VERSION ""

NS_ :

BS_:

BU_: RF_CT3

BO_ 1 Pos1_SlipAngle_Signals: 8 Vector__XXX
 SG_ Pos1_SlipAngle_20Hz : 0|16@1- (0.0013733329264,0) [-45|44.9986] "Degrees" Vector__XXX

BO_ 2 Pos2_SlipAngle_Signals: 8 Vector__XXX
 SG_ Pos2_SlipAngle_20Hz : 0|16@1- (0.0013733329264,0) [-45|44.9986] "Degrees" Vector__XXX

BO_ 3 Pos3_SlipAngle_Signals: 8 Vector__XXX
 SG_ Pos3_SlipAngle_20Hz : 0|16@1- (0.0013733329264,0) [-45|44.9986] "Degrees" Vector__XXX

BO_ 4 Pos4_SlipAngle_Signals: 8 Vector__XXX
 SG_ Pos4_SlipAngle_20Hz : 0|16@1- (0.0013733329264,0) [-45|44.9986] "Degrees" Vector__XXX

BO_ 5 Pos5_SlipAngle_Signals: 8 Vector__XXX
 SG_ Pos5_SlipAngle_20Hz : 0|16@1- (0.0013733329264,0) [-45|44.9986] "Degrees" Vector__XXX

BO_ 6 Pos6_SlipAngle_Signals: 8 Vector__XXX
 SG_ Pos6_SlipAngle_20Hz : 0|16@1- (0.0013733329264,0) [-45|44.9986] "Degrees" Vector__XXX

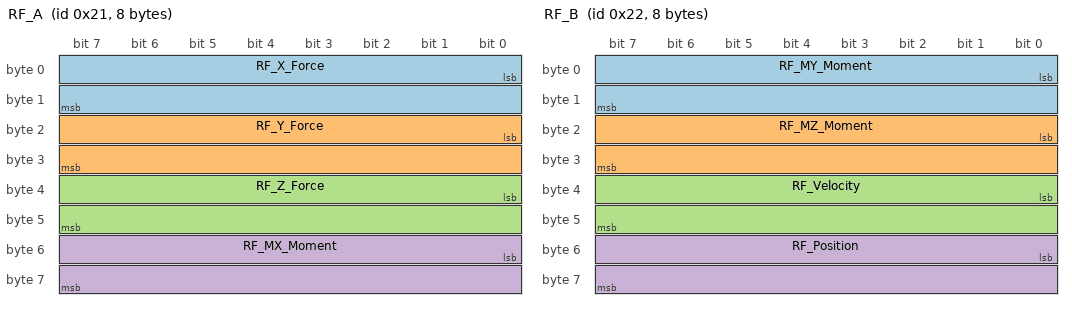
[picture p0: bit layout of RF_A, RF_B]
BO_ 33 RF_A: 8 RF_CT3
 SG_ RF_X_Force : 0|16@1- (1.220703125,0) [-40000|40000] "N" Vector__XXX
 SG_ RF_Y_Force : 16|16@1- (0.6103515625,0) [-20000|20000] "N" Vector__XXX
 SG_ RF_Z_Force : 32|16@1- (1.220703125,0) [-40000|40000] "N" Vector__XXX
 SG_ RF_MX_Moment : 48|16@1- (0.18310546875,0) [-6000|6000] "Nm" Vector__XXX

BO_ 34 RF_B: 8 RF_CT3
 SG_ RF_MY_Moment : 0|16@1- (0.18310546875,0) [-6000|6000] "Nm" Vector__XXX
 SG_ RF_MZ_Moment : 16|16@1- (0.18310546875,0) [-6000|6000] "Nm" Vector__XXX
 SG_ RF_Velocity : 32|16@1- (0.06103515625,0) [-2000|2000] "rpm" Vector__XXX
 SG_ RF_Position : 48|16@1- (0.010986328125,0) [0|360] "degrees" Vector__XXX

BO_ 35 RF_C: 8 RF_CT3
 SG_ RF_X_Acceleration : 0|16@1- (0.0030517578125,0) [-100|100] "g" Vector__XXX
 SG_ RF_Y_Acceleration : 16|16@1- (0.0030517578125,0) [-100|100] "g" Vector__XXX
 SG_ RF_Z_Acceleration : 32|16@1- (0.0030517578125,0) [-100|100] "g" Vector__XXX

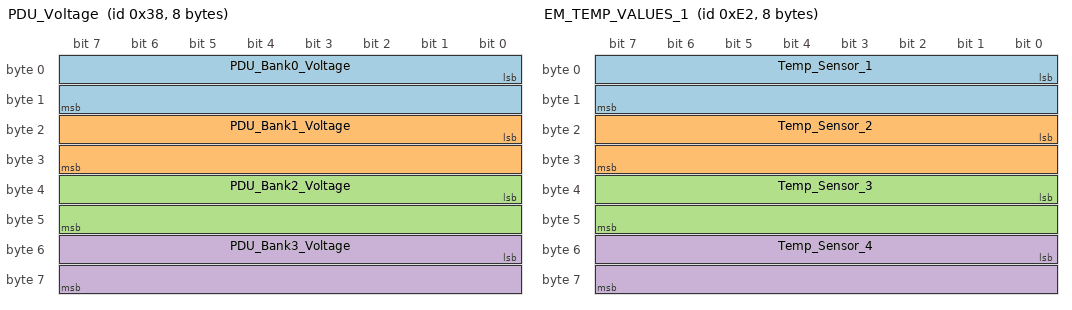
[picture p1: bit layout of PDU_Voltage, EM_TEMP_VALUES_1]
BO_ 56 PDU_Voltage: 8 PDU
 SG_ PDU_Bank0_Voltage : 0|16@1+ (0.001,0) [0|0] "V" Vector__XXX
 SG_ PDU_Bank1_Voltage : 16|16@1+ (0.001,0) [0|0] "V" Vector__XXX
 SG_ PDU_Bank2_Voltage : 32|16@1+ (0.001,0) [0|0] "V" Vector__XXX
 SG_ PDU_Bank3_Voltage : 48|16@1+ (0.001,0) [0|0] "V" Vector__XXX

BO_ 57 PDU_Currents: 8 PDU
 SG_ PDU_ChannelMux M : 0|4@1+ (1,0) [0|6] "" Vector__XXX
 SG_ PDU_Channel0 m0 : 4|12@1+ (0.0025,0) [0|0] "A" Vector__XXX
 SG_ PDU_Channel1 m0 : 16|12@1+ (0.0025,0) [0|0] "A" Vector__XXX
 SG_ PDU_Channel2 m0 : 28|12@1+ (0.0025,0) [0|0] "A" Vector__XXX
 SG_ PDU_Channel3 m0 : 40|12@1+ (0.0025,0) [0|0] "A" Vector__XXX
 SG_ PDU_Channel4 m0 : 52|12@1+ (0.0025,0) [0|0] "A" Vector__XXX
 SG_ PDU_Channel5 m1 : 4|12@1+ (0.0025,0) [0|0] "A" Vector__XXX
 SG_ PDU_Channel6 m1 : 16|12@1+ (0.0025,0) [0|0] "A" Vector__XXX
 SG_ PDU_Channel7 m1 : 28|12@1+ (0.0025,0) [0|0] "A" Vector__XXX
 SG_ PDU_Channel8 m1 : 40|12@1+ (0.0025,0) [0|0] "A" Vector__XXX
 SG_ PDU_Channel9 m1 : 52|12@1+ (0.0025,0) [0|0] "A" Vector__XXX
 SG_ PDU_Channel10 m2 : 4|12@1+ (0.0025,0) [0|0] "A" Vector__XXX
 SG_ PDU_Channel11 m2 : 16|12@1+ (0.0025,0) [0|0] "A" Vector__XXX
 SG_ PDU_Channel12 m2 : 28|12@1+ (0.0025,0) [0|0] "A" Vector__XXX
 SG_ PDU_Channel13 m2 : 40|12@1+ (0.0025,0) [0|0] "A" Vector__XXX
 SG_ PDU_Channel14 m2 : 52|12@1+ (0.0025,0) [0|0] "A" Vector__XXX
 SG_ PDU_Channel15 m3 : 4|12@1+ (0.0025,0) [0|0] "A" Vector__XXX
 SG_ PDU_Channel16 m3 : 16|12@1+ (0.0025,0) [0|0] "A" Vector__XXX
 SG_ PDU_Channel17 m3 : 28|12@1+ (0.0025,0) [0|0] "A" Vector__XXX
 SG_ PDU_Channel18 m3 : 40|12@1+ (0.0025,0) [0|0] "A" Vector__XXX
 SG_ PDU_Channel19 m3 : 52|12@1+ (0.0025,0) [0|0] "A" Vector__XXX
 SG_ PDU_Channel20 m4 : 4|12@1+ (0.0025,0) [0|0] "A" Vector__XXX
 SG_ PDU_Channel21 m4 : 16|12@1+ (0.0025,0) [0|0] "A" Vector__XXX
 SG_ PDU_Channel22 m4 : 28|12@1+ (0.0025,0) [0|0] "A" Vector__XXX
 SG_ PDU_Channel23 m4 : 40|12@1+ (0.0025,0) [0|0] "A" Vector__XXX
 SG_ PDU_Channel24 m4 : 52|12@1+ (0.0025,0) [0|0] "A" Vector__XXX
 SG_ PDU_Channel25 m5 : 4|12@1+ (0.0025,0) [0|0] "A" Vector__XXX
 SG_ PDU_Channel26 m5 : 16|12@1+ (0.0025,0) [0|0] "A" Vector__XXX
 SG_ PDU_Channel27 m5 : 28|12@1+ (0.0025,0) [0|0] "A" Vector__XXX
 SG_ PDU_Channel28 m5 : 40|12@1+ (0.0025,0) [0|0] "A" Vector__XXX
 SG_ PDU_Channel29 m5 : 52|12@1+ (0.0025,0) [0|0] "A" Vector__XXX
 SG_ PDU_Channel30 m6 : 4|12@1+ (0.0025,0) [0|0] "A" Vector__XXX
 SG_ PDU_Channel31 m6 : 16|12@1+ (0.0025,0) [0|0] "A" Vector__XXX

BO_ 226 EM_TEMP_VALUES_1: 8 Vector__XXX
 SG_ Temp_Sensor_1 : 0|16@1- (0.0625,0) [0|255] "C" Vector__XXX
 SG_ Temp_Sensor_2 : 16|16@1- (0.0625,0) [0|255] "C" Vector__XXX
 SG_ Temp_Sensor_3 : 32|16@1- (0.0625,0) [0|255] "C" Vector__XXX
 SG_ Temp_Sensor_4 : 48|16@1- (0.0625,0) [0|255] "C" Vector__XXX

BO_ 225 EM_TEMP_VALUES_2: 2 Vector_XXX
 SG_ Temp_Sensor_5 : 0|16@1- (0.0625,0) [0|255] "C" Vector__XXX

BO_ 224 EM_OUTPUT_VALUES: 8 EM
 SG_ CURRENT: 0|16@1- (0.1,0) [0|0] "A" Vector__XXX
 SG_ VOLTAGE: 16|16@1+ (0.01,0) [0|0] "V" Vector__XXX
 SG_ POWER: 32|18@1+ (1,0) [0|0] "W" Vector__XXX

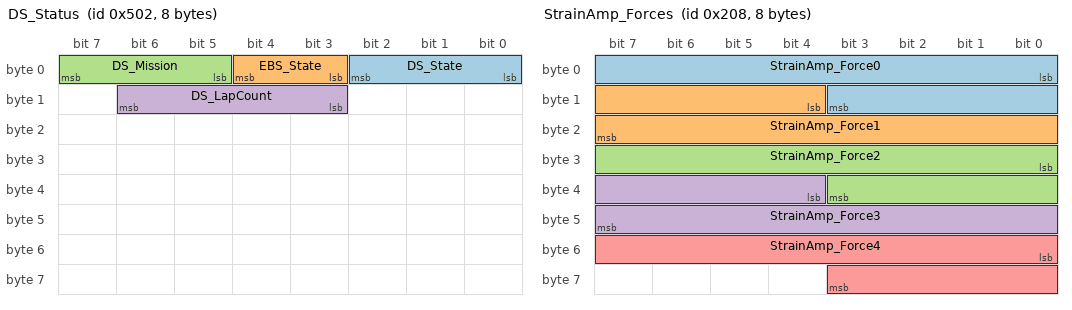
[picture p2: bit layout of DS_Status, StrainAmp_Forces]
BO_ 1282 DS_Status: 8 DS
 SG_ DS_State : 0|3@1+ (1,0) [0|0] "" Vector__XXX
 SG_ EBS_State : 3|2@1+ (1,0) [0|0] "" Vector__XXX
 SG_ DS_Mission : 5|3@1+ (1,0) [0|0] "" Vector__XXX
 SG_ DS_LapCount : 11|4@1+ (1,0) [0|0] "" Vector__XXX

BO_ 384 PIT_Pressures: 8 PIT
 SG_ PIT_PressureMux M : 0|8@1+ (1,0) [0|255] "" Vector__XXX
 SG_ PIT_Pressure1 m0 : 15|16@0+ (0.01,600) [600|1200] "mbar" Vector__XXX
 SG_ PIT_Pressure2 m0 : 31|16@0+ (0.01,600) [600|1200] "mbar" Vector__XXX
 SG_ PIT_Pressure3 m0 : 47|16@0+ (0.01,600) [600|1200] "mbar" Vector__XXX
 SG_ PIT_PressureRange m0 : 56|8@1+ (1,0) [0|3] "" Vector__XXX
 SG_ PIT_Pressure4 m1 : 15|16@0+ (0.01,600) [600|1200] "mbar" Vector__XXX
 SG_ PIT_Pressure5 m1 : 31|16@0+ (0.01,600) [600|1200] "mbar" Vector__XXX
 SG_ PIT_Pressure6 m1 : 47|16@0+ (0.01,600) [600|1200] "mbar" Vector__XXX
 SG_ PIT_Temperature m1 : 56|8@1- (1,0) [0|0] "degC" Vector__XXX
 SG_ PIT_Pressure7 m2 : 15|16@0+ (0.01,600) [600|1200] "mbar" Vector__XXX
 SG_ PIT_Pressure8 m2 : 31|16@0+ (0.01,600) [600|1200] "mbar" Vector__XXX
 SG_ PIT_SensorNum m2 : 47|16@0+ (1,0) [0|0] "" Vector__XXX

BO_ 506 OutboardAccelAvg: 6 OA
 SG_ OAAvg_AccelX : 0|16@1- (0.001,0) [-32.768|32.767] "g" Vector_XXX
 SG_ OAAvg_AccelY : 16|16@1- (0.001,0) [-32.768|32.767] "g" Vector_XXX
 SG_ OAAvg_AccelZ : 32|16@1- (0.001,0) [-32.768|32.767] "g" Vector_XXX

BO_ 507 OutboardAccelMin: 6 OA
 SG_ OAMin_AccelX : 0|16@1- (0.001,0) [-32.768|32.767] "g" Vector_XXX
 SG_ OAMin_AccelY : 16|16@1- (0.001,0) [-32.768|32.767] "g" Vector_XXX
 SG_ OAMin_AccelZ : 32|16@1- (0.001,0) [-32.768|32.767] "g" Vector_XXX

BO_ 508 OutboardAccelMax: 6 OA
 SG_ OAMax_AccelX : 0|16@1- (0.001,0) [-32.768|32.767] "g" Vector_XXX
 SG_ OAMax_AccelY : 16|16@1- (0.001,0) [-32.768|32.767] "g" Vector_XXX
 SG_ OAMax_AccelZ : 32|16@1- (0.001,0) [-32.768|32.767] "g" Vector_XXX

BO_ 520 StrainAmp_Forces: 8 SA
 SG_ StrainAmp_Force0 : 0|12@1- (2,0) [0|0] "lbf" Vector__XXX
 SG_ StrainAmp_Force1 : 12|12@1- (2,0) [0|0] "lbf" Vector__XXX
 SG_ StrainAmp_Force2 : 24|12@1- (2,0) [0|0] "lbf" Vector__XXX
 SG_ StrainAmp_Force3 : 36|12@1- (2,0) [0|0] "lbf" Vector__XXX
 SG_ StrainAmp_Force4 : 48|12@1- (2,0) [0|0] "lbf" Vector__XXX

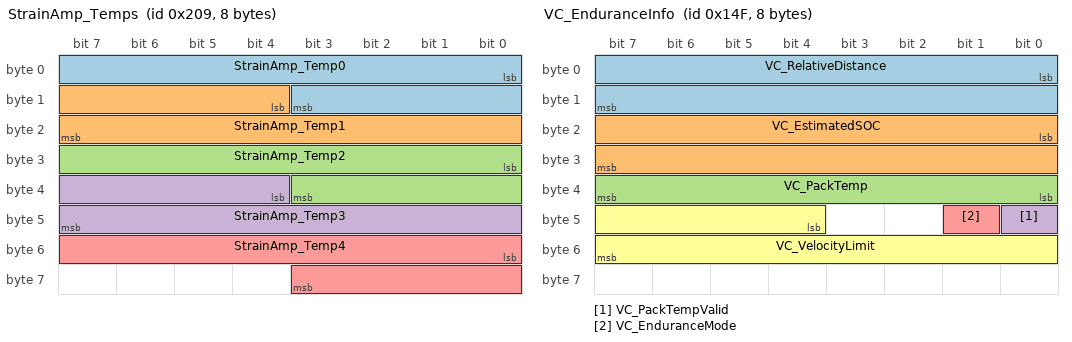
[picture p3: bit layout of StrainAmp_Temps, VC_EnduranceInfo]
BO_ 521 StrainAmp_Temps: 8 SA
 SG_ StrainAmp_Temp0 : 0|12@1- (0.05,0) [0|0] "degC" Vector__XXX
 SG_ StrainAmp_Temp1 : 12|12@1- (0.05,0) [0|0] "degC" Vector__XXX
 SG_ StrainAmp_Temp2 : 24|12@1- (0.05,0) [0|0] "degC" Vector__XXX
 SG_ StrainAmp_Temp3 : 36|12@1- (0.05,0) [0|0] "degC" Vector__XXX
 SG_ StrainAmp_Temp4 : 48|12@1- (0.05,0) [0|0] "degC" Vector__XXX

BO_ 300 VC_PDU_Control: 2 VC
 SG_ VC_Inverter_PWM : 0|5@1+ (1,0) [0|25] "" Vector__XXX
 SG_ VC_Motor_PWM : 5|5@1+ (1,0) [0|25] "" Vector__XXX

BO_ 335 VC_EnduranceInfo: 8 VC
 SG_ VC_RelativeDistance : 0|16@1+ (0.0000152587890625,0) [0|0] "" Vector__XXX
 SG_ VC_EstimatedSOC : 16|16@1+ (0.0000152587890625,0) [0|0] "" Vector__XXX
 SG_ VC_PackTemp : 32|8@1+ (0.00390625,0) [0|0] "" Vector__XXX
 SG_ VC_PackTempValid : 40|1@1+ (1,0) [0|0] "" Vector__XXX
 SG_ VC_EnduranceMode : 41|1@1+ (1,0) [0|0] "" Vector__XXX
 SG_ VC_VelocityLimit : 44|12@1+ (0.01,0) [0|0] "m/s" Vector__XXX

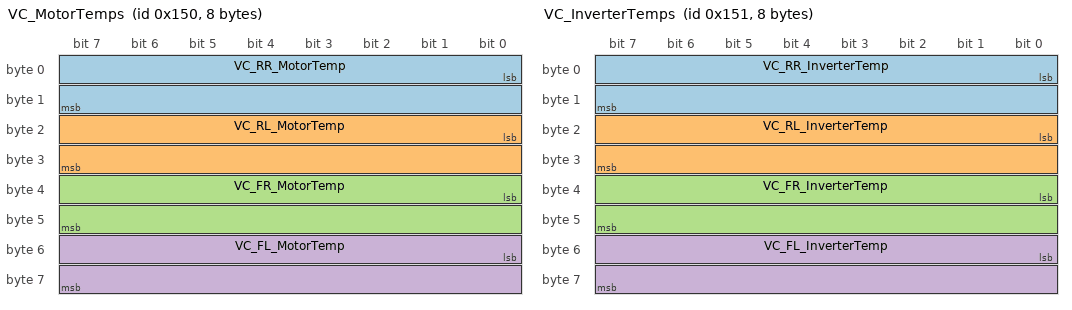
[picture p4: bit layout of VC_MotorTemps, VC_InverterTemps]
BO_ 336 VC_MotorTemps : 8 VC
 SG_ VC_RR_MotorTemp : 0|16@1- (0.1,0) [0|0] "degC" Vector__XXX
 SG_ VC_RL_MotorTemp : 16|16@1- (0.1,0) [0|0] "degC" Vector__XXX
 SG_ VC_FR_MotorTemp : 32|16@1- (0.1,0) [0|0] "degC" Vector__XXX
 SG_ VC_FL_MotorTemp : 48|16@1- (0.1,0) [0|0] "degC" Vector__XXX

BO_ 337 VC_InverterTemps : 8 VC
 SG_ VC_RR_InverterTemp : 0|16@1- (0.1,0) [0|0] "degC" Vector__XXX
 SG_ VC_RL_InverterTemp : 16|16@1- (0.1,0) [0|0] "degC" Vector__XXX
 SG_ VC_FR_InverterTemp : 32|16@1- (0.1,0) [0|0] "degC" Vector__XXX
 SG_ VC_FL_InverterTemp : 48|16@1- (0.1,0) [0|0] "degC" Vector__XXX

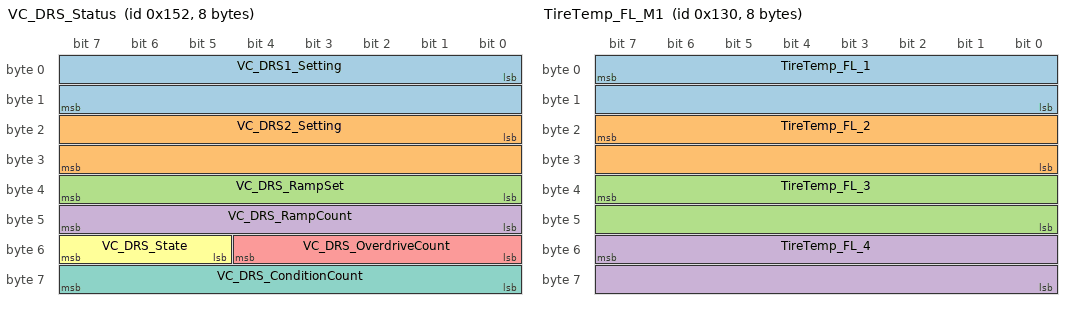
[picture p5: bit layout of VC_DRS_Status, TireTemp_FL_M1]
BO_ 338 VC_DRS_Status : 8 VC
 SG_ VC_DRS1_Setting : 0|16@1+ (1,0) [0|0] "" Vector__XXX
 SG_ VC_DRS2_Setting : 16|16@1+ (1,0) [0|0] "" Vector__XXX
 SG_ VC_DRS_RampSet : 32|8@1+ (1,0) [0|0] "" Vector__XXX
 SG_ VC_DRS_RampCount : 40|8@1+ (1,0) [0|0] "" Vector__XXX
 SG_ VC_DRS_OverdriveCount : 48|5@1+ (1,0) [0|0] "" Vector__XXX
 SG_ VC_DRS_State : 53|3@1+ (1,0) [0|0] "" Vector__XXX
 SG_ VC_DRS_ConditionCount : 56|8@1+ (1,0) [0|0] "" Vector__XXX

BO_ 304 TireTemp_FL_M1: 8 IRTEMP
 SG_ TireTemp_FL_1 : 7|16@0+ (0.1,-100) [-20|950] "degC" Vector__XXX
 SG_ TireTemp_FL_2 : 23|16@0+ (0.1,-100) [-20|950] "degC" Vector__XXX
 SG_ TireTemp_FL_3 : 39|16@0+ (0.1,-100) [-20|950] "degC" Vector__XXX
 SG_ TireTemp_FL_4 : 55|16@0+ (0.1,-100) [-20|950] "degC" Vector__XXX

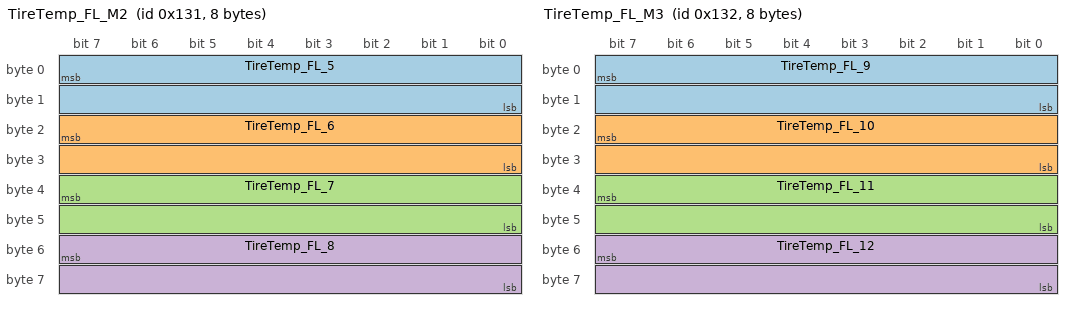
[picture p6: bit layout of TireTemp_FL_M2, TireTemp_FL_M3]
BO_ 305 TireTemp_FL_M2: 8 IRTEMP
 SG_ TireTemp_FL_5 : 7|16@0+ (0.1,-100) [-20|950] "degC" Vector__XXX
 SG_ TireTemp_FL_6 : 23|16@0+ (0.1,-100) [-20|950] "degC" Vector__XXX
 SG_ TireTemp_FL_7 : 39|16@0+ (0.1,-100) [-20|950] "degC" Vector__XXX
 SG_ TireTemp_FL_8 : 55|16@0+ (0.1,-100) [-20|950] "degC" Vector__XXX

BO_ 306 TireTemp_FL_M3: 8 IRTEMP
 SG_ TireTemp_FL_9 : 7|16@0+ (0.1,-100) [-20|950] "degC" Vector__XXX
 SG_ TireTemp_FL_10 : 23|16@0+ (0.1,-100) [-20|950] "degC" Vector__XXX
 SG_ TireTemp_FL_11 : 39|16@0+ (0.1,-100) [-20|950] "degC" Vector__XXX
 SG_ TireTemp_FL_12 : 55|16@0+ (0.1,-100) [-20|950] "degC" Vector__XXX

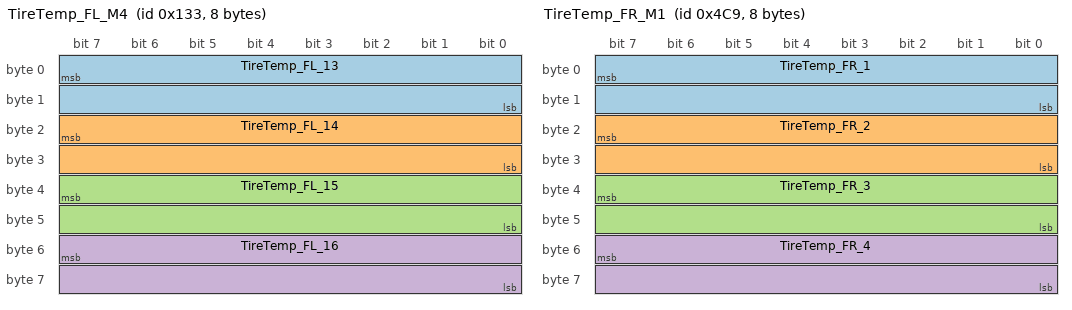
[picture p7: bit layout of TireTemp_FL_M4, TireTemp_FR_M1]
BO_ 307 TireTemp_FL_M4: 8 IRTEMP
 SG_ TireTemp_FL_13 : 7|16@0+ (0.1,-100) [-20|950] "degC" Vector__XXX
 SG_ TireTemp_FL_14 : 23|16@0+ (0.1,-100) [-20|950] "degC" Vector__XXX
 SG_ TireTemp_FL_15 : 39|16@0+ (0.1,-100) [-20|950] "degC" Vector__XXX
 SG_ TireTemp_FL_16 : 55|16@0+ (0.1,-100) [-20|950] "degC" Vector__XXX

BO_ 308 TireTemp_FL_M5: 8 IRTEMP
 SG_ TireTemp_FL_Sensor : 7|16@0+ (0.1,-100) [-20|85] "degC" Vector__XXX

BO_ 1225 TireTemp_FR_M1: 8 IRTEMP
 SG_ TireTemp_FR_1 : 7|16@0+ (0.1,-100) [-20|950] "degC" Vector__XXX
 SG_ TireTemp_FR_2 : 23|16@0+ (0.1,-100) [-20|950] "degC" Vector__XXX
 SG_ TireTemp_FR_3 : 39|16@0+ (0.1,-100) [-20|950] "degC" Vector__XXX
 SG_ TireTemp_FR_4 : 55|16@0+ (0.1,-100) [-20|950] "degC" Vector__XXX

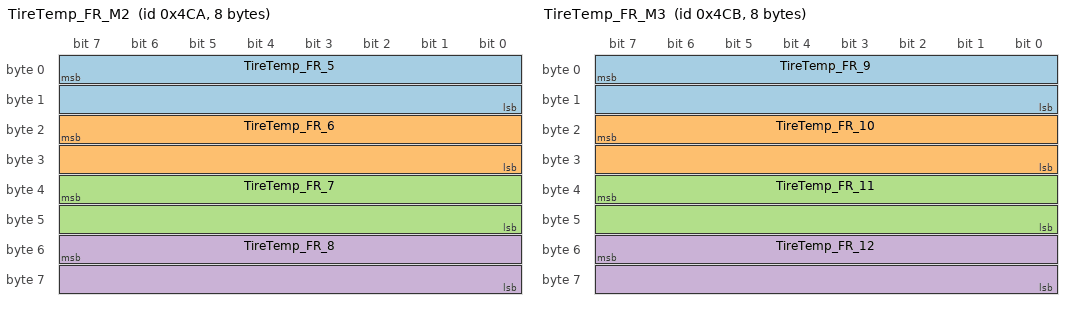
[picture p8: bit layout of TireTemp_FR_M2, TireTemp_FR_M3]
BO_ 1226 TireTemp_FR_M2: 8 IRTEMP
 SG_ TireTemp_FR_5 : 7|16@0+ (0.1,-100) [-20|950] "degC" Vector__XXX
 SG_ TireTemp_FR_6 : 23|16@0+ (0.1,-100) [-20|950] "degC" Vector__XXX
 SG_ TireTemp_FR_7 : 39|16@0+ (0.1,-100) [-20|950] "degC" Vector__XXX
 SG_ TireTemp_FR_8 : 55|16@0+ (0.1,-100) [-20|950] "degC" Vector__XXX

BO_ 1227 TireTemp_FR_M3: 8 IRTEMP
 SG_ TireTemp_FR_9 : 7|16@0+ (0.1,-100) [-20|950] "degC" Vector__XXX
 SG_ TireTemp_FR_10 : 23|16@0+ (0.1,-100) [-20|950] "degC" Vector__XXX
 SG_ TireTemp_FR_11 : 39|16@0+ (0.1,-100) [-20|950] "degC" Vector__XXX
 SG_ TireTemp_FR_12 : 55|16@0+ (0.1,-100) [-20|950] "degC" Vector__XXX

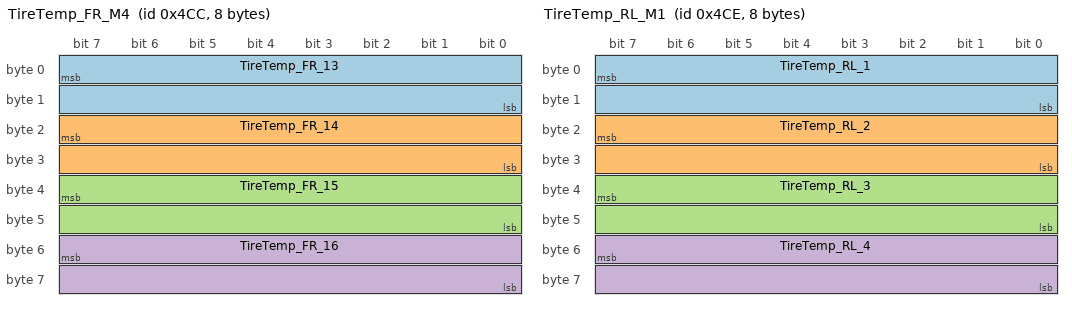
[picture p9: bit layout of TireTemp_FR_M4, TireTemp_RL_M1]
BO_ 1228 TireTemp_FR_M4: 8 IRTEMP
 SG_ TireTemp_FR_13 : 7|16@0+ (0.1,-100) [-20|950] "degC" Vector__XXX
 SG_ TireTemp_FR_14 : 23|16@0+ (0.1,-100) [-20|950] "degC" Vector__XXX
 SG_ TireTemp_FR_15 : 39|16@0+ (0.1,-100) [-20|950] "degC" Vector__XXX
 SG_ TireTemp_FR_16 : 55|16@0+ (0.1,-100) [-20|950] "degC" Vector__XXX

BO_ 1229 TireTemp_FR_M5: 8 IRTEMP
 SG_ TireTemp_FR_Sensor : 7|16@0+ (0.1,-100) [-20|85] "degC" Vector__XXX

BO_ 1230 TireTemp_RL_M1: 8 IRTEMP
 SG_ TireTemp_RL_1 : 7|16@0+ (0.1,-100) [-20|950] "degC" Vector__XXX
 SG_ TireTemp_RL_2 : 23|16@0+ (0.1,-100) [-20|950] "degC" Vector__XXX
 SG_ TireTemp_RL_3 : 39|16@0+ (0.1,-100) [-20|950] "degC" Vector__XXX
 SG_ TireTemp_RL_4 : 55|16@0+ (0.1,-100) [-20|950] "degC" Vector__XXX

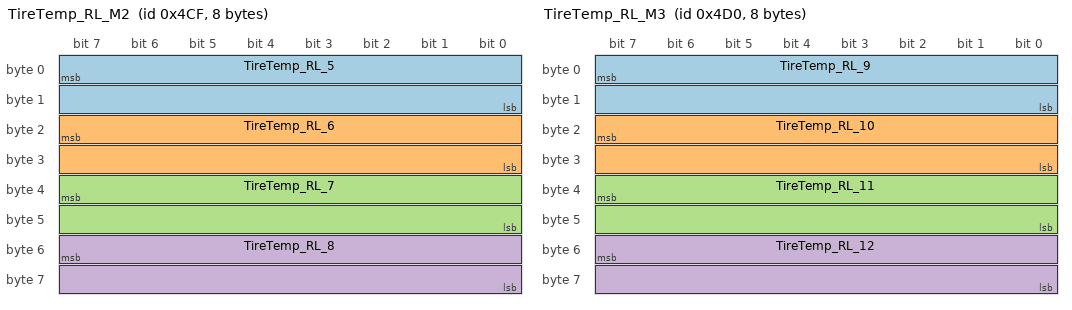
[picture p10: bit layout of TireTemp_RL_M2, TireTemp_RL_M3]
BO_ 1231 TireTemp_RL_M2: 8 IRTEMP
 SG_ TireTemp_RL_5 : 7|16@0+ (0.1,-100) [-20|950] "degC" Vector__XXX
 SG_ TireTemp_RL_6 : 23|16@0+ (0.1,-100) [-20|950] "degC" Vector__XXX
 SG_ TireTemp_RL_7 : 39|16@0+ (0.1,-100) [-20|950] "degC" Vector__XXX
 SG_ TireTemp_RL_8 : 55|16@0+ (0.1,-100) [-20|950] "degC" Vector__XXX

BO_ 1232 TireTemp_RL_M3: 8 IRTEMP
 SG_ TireTemp_RL_9 : 7|16@0+ (0.1,-100) [-20|950] "degC" Vector__XXX
 SG_ TireTemp_RL_10 : 23|16@0+ (0.1,-100) [-20|950] "degC" Vector__XXX
 SG_ TireTemp_RL_11 : 39|16@0+ (0.1,-100) [-20|950] "degC" Vector__XXX
 SG_ TireTemp_RL_12 : 55|16@0+ (0.1,-100) [-20|950] "degC" Vector__XXX

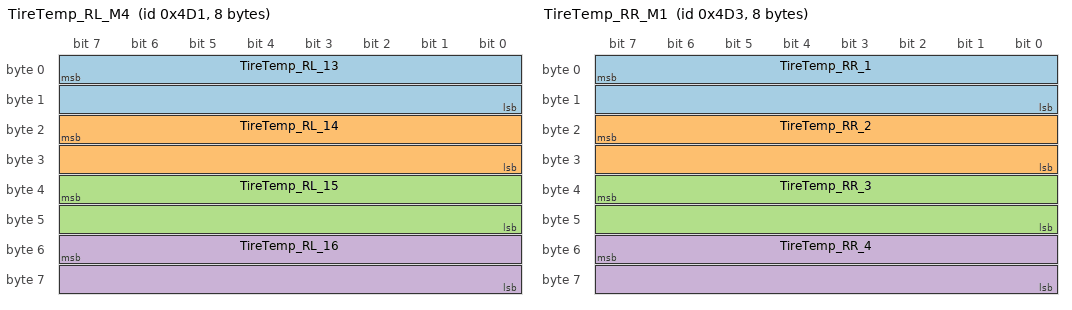
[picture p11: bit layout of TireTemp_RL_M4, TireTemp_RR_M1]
BO_ 1233 TireTemp_RL_M4: 8 IRTEMP
 SG_ TireTemp_RL_13 : 7|16@0+ (0.1,-100) [-20|950] "degC" Vector__XXX
 SG_ TireTemp_RL_14 : 23|16@0+ (0.1,-100) [-20|950] "degC" Vector__XXX
 SG_ TireTemp_RL_15 : 39|16@0+ (0.1,-100) [-20|950] "degC" Vector__XXX
 SG_ TireTemp_RL_16 : 55|16@0+ (0.1,-100) [-20|950] "degC" Vector__XXX

BO_ 1234 TireTemp_RL_M5: 8 IRTEMP
 SG_ TireTemp_RL_Sensor : 7|16@0+ (0.1,-100) [-20|85] "degC" Vector__XXX

BO_ 1235 TireTemp_RR_M1: 8 IRTEMP
 SG_ TireTemp_RR_1 : 7|16@0+ (0.1,-100) [-20|950] "degC" Vector__XXX
 SG_ TireTemp_RR_2 : 23|16@0+ (0.1,-100) [-20|950] "degC" Vector__XXX
 SG_ TireTemp_RR_3 : 39|16@0+ (0.1,-100) [-20|950] "degC" Vector__XXX
 SG_ TireTemp_RR_4 : 55|16@0+ (0.1,-100) [-20|950] "degC" Vector__XXX

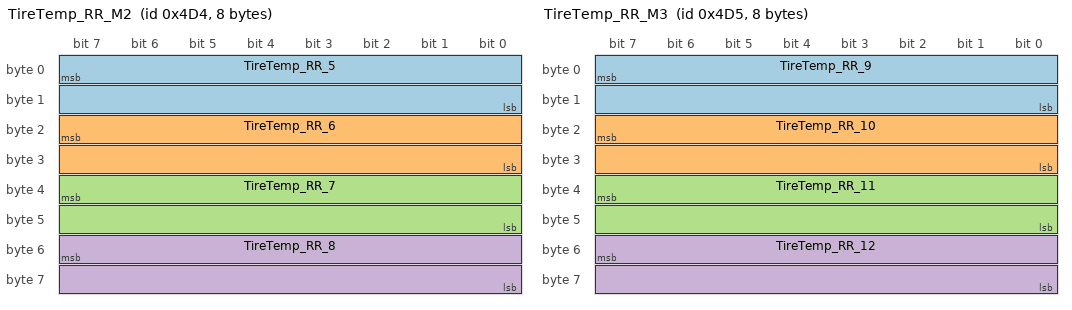
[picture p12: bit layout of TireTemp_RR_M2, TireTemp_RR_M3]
BO_ 1236 TireTemp_RR_M2: 8 IRTEMP
 SG_ TireTemp_RR_5 : 7|16@0+ (0.1,-100) [-20|950] "degC" Vector__XXX
 SG_ TireTemp_RR_6 : 23|16@0+ (0.1,-100) [-20|950] "degC" Vector__XXX
 SG_ TireTemp_RR_7 : 39|16@0+ (0.1,-100) [-20|950] "degC" Vector__XXX
 SG_ TireTemp_RR_8 : 55|16@0+ (0.1,-100) [-20|950] "degC" Vector__XXX

BO_ 1237 TireTemp_RR_M3: 8 IRTEMP
 SG_ TireTemp_RR_9 : 7|16@0+ (0.1,-100) [-20|950] "degC" Vector__XXX
 SG_ TireTemp_RR_10 : 23|16@0+ (0.1,-100) [-20|950] "degC" Vector__XXX
 SG_ TireTemp_RR_11 : 39|16@0+ (0.1,-100) [-20|950] "degC" Vector__XXX
 SG_ TireTemp_RR_12 : 55|16@0+ (0.1,-100) [-20|950] "degC" Vector__XXX

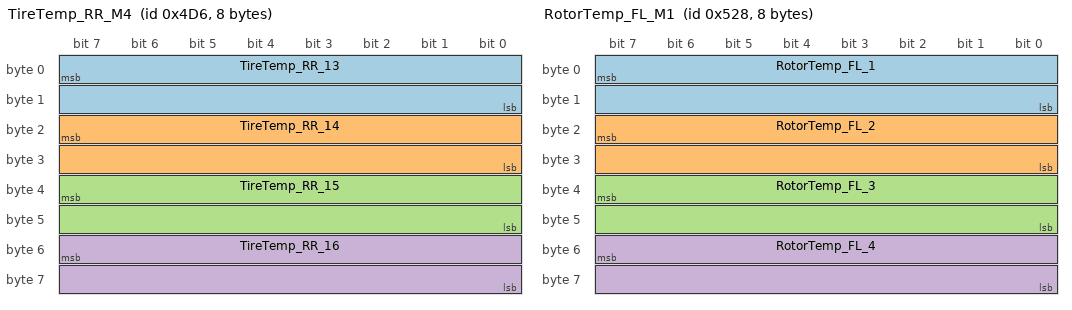
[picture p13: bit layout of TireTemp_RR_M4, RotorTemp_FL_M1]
BO_ 1238 TireTemp_RR_M4: 8 IRTEMP
 SG_ TireTemp_RR_13 : 7|16@0+ (0.1,-100) [-20|950] "degC" Vector__XXX
 SG_ TireTemp_RR_14 : 23|16@0+ (0.1,-100) [-20|950] "degC" Vector__XXX
 SG_ TireTemp_RR_15 : 39|16@0+ (0.1,-100) [-20|950] "degC" Vector__XXX
 SG_ TireTemp_RR_16 : 55|16@0+ (0.1,-100) [-20|950] "degC" Vector__XXX

BO_ 1239 TireTemp_RR_M5: 8 IRTEMP
 SG_ TireTemp_RR_Sensor : 7|16@0+ (0.1,-100) [-20|85] "degC" Vector__XXX

BO_ 1320 RotorTemp_FL_M1: 8 IRTEMP
 SG_ RotorTemp_FL_1 : 7|16@0+ (0.1,-100) [-20|950] "degC" Vector__XXX
 SG_ RotorTemp_FL_2 : 23|16@0+ (0.1,-100) [-20|950] "degC" Vector__XXX
 SG_ RotorTemp_FL_3 : 39|16@0+ (0.1,-100) [-20|950] "degC" Vector__XXX
 SG_ RotorTemp_FL_4 : 55|16@0+ (0.1,-100) [-20|950] "degC" Vector__XXX

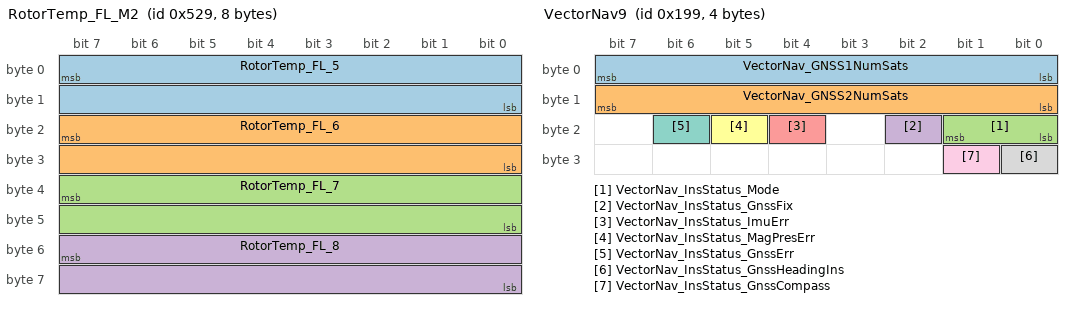
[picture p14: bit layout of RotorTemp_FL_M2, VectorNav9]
BO_ 1321 RotorTemp_FL_M2: 8 IRTEMP
 SG_ RotorTemp_FL_5 : 7|16@0+ (0.1,-100) [-20|950] "degC" Vector__XXX
 SG_ RotorTemp_FL_6 : 23|16@0+ (0.1,-100) [-20|950] "degC" Vector__XXX
 SG_ RotorTemp_FL_7 : 39|16@0+ (0.1,-100) [-20|950] "degC" Vector__XXX
 SG_ RotorTemp_FL_8 : 55|16@0+ (0.1,-100) [-20|950] "degC" Vector__XXX

BO_ 1322 RotorTemp_FL_M3: 8 IRTEMP
 SG_ RotorTemp_FL_9 : 7|16@0+ (0.1,-100) [-20|950] "degC" Vector__XXX
 SG_ RotorTemp_FL_10 : 23|16@0+ (0.1,-100) [-20|950] "degC" Vector__XXX
 SG_ RotorTemp_FL_11 : 39|16@0+ (0.1,-100) [-20|950] "degC" Vector__XXX
 SG_ RotorTemp_FL_12 : 55|16@0+ (0.1,-100) [-20|950] "degC" Vector__XXX

BO_ 1323 RotorTemp_FL_M4: 8 IRTEMP
 SG_ RotorTemp_FL_13 : 7|16@0+ (0.1,-100) [-20|950] "degC" Vector__XXX
 SG_ RotorTemp_FL_14 : 23|16@0+ (0.1,-100) [-20|950] "degC" Vector__XXX
 SG_ RotorTemp_FL_15 : 39|16@0+ (0.1,-100) [-20|950] "degC" Vector__XXX
 SG_ RotorTemp_FL_16 : 55|16@0+ (0.1,-100) [-20|950] "degC" Vector__XXX

BO_ 1324 RotorTemp_FL_M5: 8 IRTEMP
 SG_ RotorTemp_FL_Sensor : 7|16@0+ (0.1,-100) [-20|85] "degC" Vector__XXX

BO_ 1325 RotorTemp_FR_M1: 8 IRTEMP
 SG_ RotorTemp_FR_1 : 7|16@0+ (0.1,-100) [-20|950] "degC" Vector__XXX
 SG_ RotorTemp_FR_2 : 23|16@0+ (0.1,-100) [-20|950] "degC" Vector__XXX
 SG_ RotorTemp_FR_3 : 39|16@0+ (0.1,-100) [-20|950] "degC" Vector__XXX
 SG_ RotorTemp_FR_4 : 55|16@0+ (0.1,-100) [-20|950] "degC" Vector__XXX

BO_ 1326 RotorTemp_FR_M2: 8 IRTEMP
 SG_ RotorTemp_FR_5 : 7|16@0+ (0.1,-100) [-20|950] "degC" Vector__XXX
 SG_ RotorTemp_FR_6 : 23|16@0+ (0.1,-100) [-20|950] "degC" Vector__XXX
 SG_ RotorTemp_FR_7 : 39|16@0+ (0.1,-100) [-20|950] "degC" Vector__XXX
 SG_ RotorTemp_FR_8 : 55|16@0+ (0.1,-100) [-20|950] "degC" Vector__XXX

BO_ 1327 RotorTemp_FR_M3: 8 IRTEMP
 SG_ RotorTemp_FR_9 : 7|16@0+ (0.1,-100) [-20|950] "degC" Vector__XXX
 SG_ RotorTemp_FR_10 : 23|16@0+ (0.1,-100) [-20|950] "degC" Vector__XXX
 SG_ RotorTemp_FR_11 : 39|16@0+ (0.1,-100) [-20|950] "degC" Vector__XXX
 SG_ RotorTemp_FR_12 : 55|16@0+ (0.1,-100) [-20|950] "degC" Vector__XXX

BO_ 1328 RotorTemp_FR_M4: 8 IRTEMP
 SG_ RotorTemp_FR_13 : 7|16@0+ (0.1,-100) [-20|950] "degC" Vector__XXX
 SG_ RotorTemp_FR_14 : 23|16@0+ (0.1,-100) [-20|950] "degC" Vector__XXX
 SG_ RotorTemp_FR_15 : 39|16@0+ (0.1,-100) [-20|950] "degC" Vector__XXX
 SG_ RotorTemp_FR_16 : 55|16@0+ (0.1,-100) [-20|950] "degC" Vector__XXX

BO_ 1329 RotorTemp_FR_M5: 8 IRTEMP
 SG_ RotorTemp_FR_Sensor : 7|16@0+ (0.1,-100) [-20|85] "degC" Vector__XXX

BO_ 1330 RotorTemp_RL_M1: 8 IRTEMP
 SG_ RotorTemp_RL_1 : 7|16@0+ (0.1,-100) [-20|950] "degC" Vector__XXX
 SG_ RotorTemp_RL_2 : 23|16@0+ (0.1,-100) [-20|950] "degC" Vector__XXX
 SG_ RotorTemp_RL_3 : 39|16@0+ (0.1,-100) [-20|950] "degC" Vector__XXX
 SG_ RotorTemp_RL_4 : 55|16@0+ (0.1,-100) [-20|950] "degC" Vector__XXX

BO_ 1331 RotorTemp_RL_M2: 8 IRTEMP
 SG_ RotorTemp_RL_5 : 7|16@0+ (0.1,-100) [-20|950] "degC" Vector__XXX
 SG_ RotorTemp_RL_6 : 23|16@0+ (0.1,-100) [-20|950] "degC" Vector__XXX
 SG_ RotorTemp_RL_7 : 39|16@0+ (0.1,-100) [-20|950] "degC" Vector__XXX
 SG_ RotorTemp_RL_8 : 55|16@0+ (0.1,-100) [-20|950] "degC" Vector__XXX

BO_ 1332 RotorTemp_RL_M3: 8 IRTEMP
 SG_ RotorTemp_RL_9 : 7|16@0+ (0.1,-100) [-20|950] "degC" Vector__XXX
 SG_ RotorTemp_RL_10 : 23|16@0+ (0.1,-100) [-20|950] "degC" Vector__XXX
 SG_ RotorTemp_RL_11 : 39|16@0+ (0.1,-100) [-20|950] "degC" Vector__XXX
 SG_ RotorTemp_RL_12 : 55|16@0+ (0.1,-100) [-20|950] "degC" Vector__XXX

BO_ 1333 RotorTemp_RL_M4: 8 IRTEMP
 SG_ RotorTemp_RL_13 : 7|16@0+ (0.1,-100) [-20|950] "degC" Vector__XXX
 SG_ RotorTemp_RL_14 : 23|16@0+ (0.1,-100) [-20|950] "degC" Vector__XXX
 SG_ RotorTemp_RL_15 : 39|16@0+ (0.1,-100) [-20|950] "degC" Vector__XXX
 SG_ RotorTemp_RL_16 : 55|16@0+ (0.1,-100) [-20|950] "degC" Vector__XXX

BO_ 1334 RotorTemp_RL_M5: 8 IRTEMP
 SG_ RotorTemp_RL_Sensor : 7|16@0+ (0.1,-100) [-20|85] "degC" Vector__XXX

BO_ 1335 RotorTemp_RR_M1: 8 IRTEMP
 SG_ RotorTemp_RR_1 : 7|16@0+ (0.1,-100) [-20|950] "degC" Vector__XXX
 SG_ RotorTemp_RR_2 : 23|16@0+ (0.1,-100) [-20|950] "degC" Vector__XXX
 SG_ RotorTemp_RR_3 : 39|16@0+ (0.1,-100) [-20|950] "degC" Vector__XXX
 SG_ RotorTemp_RR_4 : 55|16@0+ (0.1,-100) [-20|950] "degC" Vector__XXX

BO_ 1336 RotorTemp_RR_M2: 8 IRTEMP
 SG_ RotorTemp_RR_5 : 7|16@0+ (0.1,-100) [-20|950] "degC" Vector__XXX
 SG_ RotorTemp_RR_6 : 23|16@0+ (0.1,-100) [-20|950] "degC" Vector__XXX
 SG_ RotorTemp_RR_7 : 39|16@0+ (0.1,-100) [-20|950] "degC" Vector__XXX
 SG_ RotorTemp_RR_8 : 55|16@0+ (0.1,-100) [-20|950] "degC" Vector__XXX

BO_ 1337 RotorTemp_RR_M3: 8 IRTEMP
 SG_ RotorTemp_RR_9 : 7|16@0+ (0.1,-100) [-20|950] "degC" Vector__XXX
 SG_ RotorTemp_RR_10 : 23|16@0+ (0.1,-100) [-20|950] "degC" Vector__XXX
 SG_ RotorTemp_RR_11 : 39|16@0+ (0.1,-100) [-20|950] "degC" Vector__XXX
 SG_ RotorTemp_RR_12 : 55|16@0+ (0.1,-100) [-20|950] "degC" Vector__XXX

BO_ 1338 RotorTemp_RR_M4: 8 IRTEMP
 SG_ RotorTemp_RR_13 : 7|16@0+ (0.1,-100) [-20|950] "degC" Vector__XXX
 SG_ RotorTemp_RR_14 : 23|16@0+ (0.1,-100) [-20|950] "degC" Vector__XXX
 SG_ RotorTemp_RR_15 : 39|16@0+ (0.1,-100) [-20|950] "degC" Vector__XXX
 SG_ RotorTemp_RR_16 : 55|16@0+ (0.1,-100) [-20|950] "degC" Vector__XXX

BO_ 1339 RotorTemp_RR_M5: 8 IRTEMP
 SG_ RotorTemp_RR_Sensor : 7|16@0+ (0.1,-100) [-20|85] "degC" Vector__XXX

BO_ 428 LoadCell_RR : 8 LCRR
 SG_ LoadCell_RR_Raw : 7|16@0- (1,0) [0|0] "uV" Vector__XXX
 SG_ LoadCell_RR_Force : 23|16@0- (0.1,0) [0|0] "" Vector__XXX
 SG_ LoadCell_RR_IntTemp : 39|16@0+ (0.1,0) [0|0] "degC" Vector__XXX
 SG_ LoadCell_RR_ExtTemp : 55|16@0+ (0.1,0) [0|0] "degC" Vector__XXX

BO_ 424 LoadCell_RL : 8 LCRL
 SG_ LoadCell_RL_Raw : 7|16@0- (1,0) [0|0] "uV" Vector__XXX
 SG_ LoadCell_RL_Force : 23|16@0- (0.1,0) [0|0] "" Vector__XXX
 SG_ LoadCell_RL_IntTemp : 39|16@0+ (0.1,0) [0|0] "degC" Vector__XXX
 SG_ LoadCell_RL_ExtTemp : 55|16@0+ (0.1,0) [0|0] "degC" Vector__XXX

BO_ 420 LoadCell_FR : 8 LCFL
 SG_ LoadCell_FR_Raw : 7|16@0- (1,0) [0|0] "uV" Vector__XXX
 SG_ LoadCell_FR_Force : 23|16@0- (0.1,0) [0|0] "" Vector__XXX
 SG_ LoadCell_FR_IntTemp : 39|16@0+ (0.1,0) [0|0] "degC" Vector__XXX
 SG_ LoadCell_FR_ExtTemp : 55|16@0+ (0.1,0) [0|0] "degC" Vector__XXX

BO_ 432 LoadCell_FL : 8 LCFL
 SG_ LoadCell_FL_Raw : 7|16@0- (1,0) [0|0] "uV" Vector__XXX
 SG_ LoadCell_FL_Force : 23|16@0- (0.1,0) [0|0] "" Vector__XXX
 SG_ LoadCell_FL_IntTemp : 39|16@0+ (0.1,0) [0|0] "degC" Vector__XXX
 SG_ LoadCell_FL_ExtTemp : 55|16@0+ (0.1,0) [0|0] "degC" Vector__XXX

BO_ 400 VectorNav0: 8 VectorNav
 SG_ VectorNav_AccelX : 0|32@1+ (1,0) [0|0] "m/s^2" Vector__XXX
 SG_ VectorNav_AccelY : 32|32@1+ (1,0) [0|0] "m/s^2" Vector__XXX

BO_ 401 VectorNav1: 8 VectorNav
 SG_ VectorNav_AccelZ : 0|32@1+ (1,0) [0|0] "m/s^2" Vector__XXX
 SG_ VectorNav_AngularRateX : 32|32@1+ (1,0) [0|0] "rad/s" Vector__XXX

BO_ 402 VectorNav2: 8 VectorNav
 SG_ VectorNav_AngularRateY : 0|32@1+ (1,0) [0|0] "rad/s" Vector__XXX
 SG_ VectorNav_AngularRateZ : 32|32@1+ (1,0) [0|0] "rad/s" Vector__XXX

BO_ 403 VectorNav3: 8 VectorNav
 SG_ VectorNav_PosLlaL : 0|64@1+ (1,0) [0|0] "deg" Vector__XXX

BO_ 404 VectorNav4: 8 VectorNav
 SG_ VectorNav_PosLlaO : 0|64@1+ (1,0) [0|0] "deg" Vector__XXX

BO_ 405 VectorNav5: 8 VectorNav
 SG_ VectorNav_PosLlaA : 0|64@1+ (1,0) [0|0] "m" Vector__XXX

BO_ 406 VectorNav6: 8 VectorNav
 SG_ VectorNav_VelBodyX : 0|32@1+ (1,0) [0|0] "m/s" Vector__XXX
 SG_ VectorNav_VelBodyY : 32|32@1+ (1,0) [0|0] "m/s" Vector__XXX

BO_ 407 VectorNav7: 8 VectorNav
 SG_ VectorNav_VelBodyZ : 0|32@1+ (1,0) [0|0] "m/s" Vector__XXX
 SG_ VectorNav_YprY : 32|32@1+ (1,0) [0|0] "deg" Vector__XXX

BO_ 408 VectorNav8: 8 VectorNav
 SG_ VectorNav_YprP : 0|32@1+ (1,0) [0|0] "deg" Vector__XXX
 SG_ VectorNav_YprR : 32|32@1+ (1,0) [0|0] "deg" Vector__XXX

BO_ 409 VectorNav9: 4 VectorNav
 SG_ VectorNav_GNSS1NumSats : 0|8@1+ (1,0) [0|255] "" Vector__XXX
 SG_ VectorNav_GNSS2NumSats : 8|8@1+ (1,0) [0|255] "" Vector__XXX
 SG_ VectorNav_InsStatus_Mode : 16|2@1+ (1,0) [0|2] "" Vector__XXX
 SG_ VectorNav_InsStatus_GnssFix : 18|1@1+ (1,0) [0|1] "" Vector__XXX
 SG_ VectorNav_InsStatus_ImuErr : 20|1@1+ (1,0) [0|1] "" Vector__XXX
 SG_ VectorNav_InsStatus_MagPresErr : 21|1@1+ (1,0) [0|1] "" Vector__XXX
 SG_ VectorNav_InsStatus_GnssErr : 22|1@1+ (1,0) [0|1] "" Vector__XXX
 SG_ VectorNav_InsStatus_GnssHeadingIns : 24|1@1+ (1,0) [0|1] "" Vector__XXX
 SG_ VectorNav_InsStatus_GnssCompass : 25|1@1+ (1,0) [0|1] "" Vector__XXX

BO_ 410 VectorNav10: 8 VectorNav
 SG_ VectorNav_BodySlip : 0|32@1+ (1,0) [0|0] "" Vector__XXX

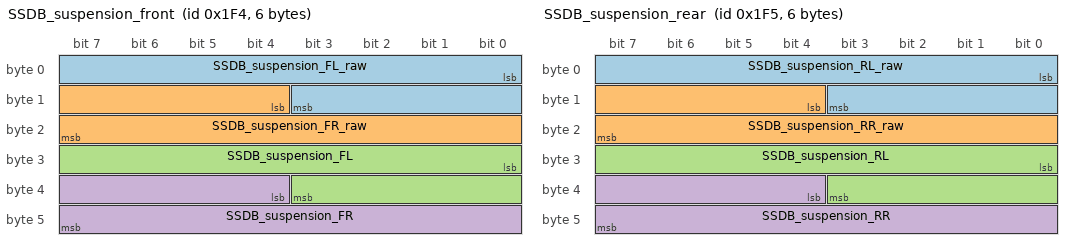
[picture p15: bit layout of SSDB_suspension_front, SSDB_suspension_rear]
BO_ 500 SSDB_suspension_front: 6 SSDB
 SG_ SSDB_suspension_FL_raw : 0|12@1+ (1,0) [0|4095] "" Vector__XXX
 SG_ SSDB_suspension_FR_raw : 12|12@1+ (1,0) [0|4095] "" Vector__XXX
 SG_ SSDB_suspension_FL : 24|12@1+ (0.005,0) [0|0] "in" Vector__XXX
 SG_ SSDB_suspension_FR : 36|12@1+ (0.005,0) [0|0] "in" Vector__XXX

BO_ 501 SSDB_suspension_rear: 6 SSDB
 SG_ SSDB_suspension_RL_raw : 0|12@1+ (1,0) [0|4095] "" Vector__XXX
 SG_ SSDB_suspension_RR_raw : 12|12@1+ (1,0) [0|4095] "" Vector__XXX
 SG_ SSDB_suspension_RL : 24|12@1+ (0.005,0) [0|0] "in" Vector__XXX
 SG_ SSDB_suspension_RR : 36|12@1+ (0.005,0) [0|0] "in" Vector__XXX

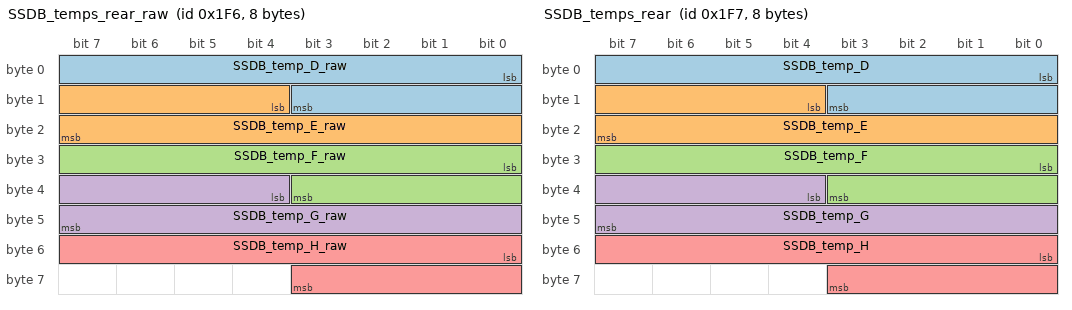
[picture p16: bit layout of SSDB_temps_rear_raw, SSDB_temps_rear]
BO_ 502 SSDB_temps_rear_raw: 8 SSDB
 SG_ SSDB_temp_D_raw : 0|12@1+ (1,0) [0|0] "" Vector__XXX
 SG_ SSDB_temp_E_raw : 12|12@1+ (1,0) [0|0] "" Vector__XXX
 SG_ SSDB_temp_F_raw : 24|12@1+ (1,0) [0|0] "" Vector__XXX
 SG_ SSDB_temp_G_raw : 36|12@1+ (1,0) [0|0] "" Vector__XXX
 SG_ SSDB_temp_H_raw : 48|12@1+ (1,0) [0|0] "" Vector__XXX

BO_ 503 SSDB_temps_rear: 8 SSDB
 SG_ SSDB_temp_D : 0|12@1- (0.1,0) [0|0] "degC" Vector__XXX
 SG_ SSDB_temp_E : 12|12@1- (0.1,0) [0|0] "degC" Vector__XXX
 SG_ SSDB_temp_F : 24|12@1- (0.1,0) [0|0] "degC" Vector__XXX
 SG_ SSDB_temp_G : 36|12@1- (0.1,0) [0|0] "degC" Vector__XXX
 SG_ SSDB_temp_H : 48|12@1- (0.1,0) [0|0] "degC" Vector__XXX

BO_ 510 DASH_inputs: 1 DASH
 SG_ DASH_Button1 : 0|1@1+ (1,0) [0|0] "" Vector__XXX
 SG_ DASH_Button2 : 1|1@1+ (1,0) [0|0] "" Vector__XXX

BO_ 620 BMS_Voltages: 8 BMS
 SG_ BMS_Voltages_mux M : 0|5@1+ (1,0) [0|22] "" Vector__XXX
 SG_ BMS_Voltages_A0 m0 : 5|9@1+ (0.01,0) [0|5.12] "V" Vector__XXX
 SG_ BMS_Voltages_A1 m0 : 14|9@1+ (0.01,0) [0|5.12] "V" Vector__XXX
 SG_ BMS_Voltages_A2 m0 : 23|9@1+ (0.01,0) [0|5.12] "V" Vector__XXX
 SG_ BMS_Voltages_A3 m0 : 32|9@1+ (0.01,0) [0|5.12] "V" Vector__XXX
 SG_ BMS_Voltages_A4 m0 : 41|9@1+ (0.01,0) [0|5.12] "V" Vector__XXX
 SG_ BMS_Voltages_A5 m0 : 50|9@1+ (0.01,0) [0|5.12] "V" Vector__XXX
 SG_ BMS_Voltages_A6 m1 : 5|9@1+ (0.01,0) [0|5.12] "V" Vector__XXX
 SG_ BMS_Voltages_A7 m1 : 14|9@1+ (0.01,0) [0|5.12] "V" Vector__XXX
 SG_ BMS_Voltages_A8 m1 : 23|9@1+ (0.01,0) [0|5.12] "V" Vector__XXX
 SG_ BMS_Voltages_A9 m1 : 32|9@1+ (0.01,0) [0|5.12] "V" Vector__XXX
 SG_ BMS_Voltages_A10 m1 : 41|9@1+ (0.01,0) [0|5.12] "V" Vector__XXX
 SG_ BMS_Voltages_A11 m1 : 50|9@1+ (0.01,0) [0|5.12] "V" Vector__XXX
 SG_ BMS_Voltages_A12 m2 : 5|9@1+ (0.01,0) [0|5.12] "V" Vector__XXX
 SG_ BMS_Voltages_A13 m2 : 14|9@1+ (0.01,0) [0|5.12] "V" Vector__XXX
 SG_ BMS_Voltages_A14 m2 : 23|9@1+ (0.01,0) [0|5.12] "V" Vector__XXX
 SG_ BMS_Voltages_A15 m2 : 32|9@1+ (0.01,0) [0|5.12] "V" Vector__XXX
 SG_ BMS_Voltages_A16 m2 : 41|9@1+ (0.01,0) [0|5.12] "V" Vector__XXX
 SG_ BMS_Voltages_A17 m2 : 50|9@1+ (0.01,0) [0|5.12] "V" Vector__XXX
 SG_ BMS_Voltages_A18 m3 : 5|9@1+ (0.01,0) [0|5.12] "V" Vector__XXX
 SG_ BMS_Voltages_A19 m3 : 14|9@1+ (0.01,0) [0|5.12] "V" Vector__XXX
 SG_ BMS_Voltages_A20 m3 : 23|9@1+ (0.01,0) [0|5.12] "V" Vector__XXX
 SG_ BMS_Voltages_A21 m3 : 32|9@1+ (0.01,0) [0|5.12] "V" Vector__XXX
 SG_ BMS_Voltages_A22 m3 : 41|9@1+ (0.01,0) [0|5.12] "V" Vector__XXX
 SG_ BMS_Voltages_A23 m3 : 50|9@1+ (0.01,0) [0|5.12] "V" Vector__XXX
 SG_ BMS_Voltages_A24 m4 : 5|9@1+ (0.01,0) [0|5.12] "V" Vector__XXX
 SG_ BMS_Voltages_A25 m4 : 14|9@1+ (0.01,0) [0|5.12] "V" Vector__XXX
 SG_ BMS_Voltages_A26 m4 : 23|9@1+ (0.01,0) [0|5.12] "V" Vector__XXX
 SG_ BMS_Voltages_B0 m4 : 32|9@1+ (0.01,0) [0|5.12] "V" Vector__XXX
 SG_ BMS_Voltages_B1 m4 : 41|9@1+ (0.01,0) [0|5.12] "V" Vector__XXX
 SG_ BMS_Voltages_B2 m4 : 50|9@1+ (0.01,0) [0|5.12] "V" Vector__XXX
 SG_ BMS_Voltages_B3 m5 : 5|9@1+ (0.01,0) [0|5.12] "V" Vector__XXX
 SG_ BMS_Voltages_B4 m5 : 14|9@1+ (0.01,0) [0|5.12] "V" Vector__XXX
 SG_ BMS_Voltages_B5 m5 : 23|9@1+ (0.01,0) [0|5.12] "V" Vector__XXX
 SG_ BMS_Voltages_B6 m5 : 32|9@1+ (0.01,0) [0|5.12] "V" Vector__XXX
 SG_ BMS_Voltages_B7 m5 : 41|9@1+ (0.01,0) [0|5.12] "V" Vector__XXX
 SG_ BMS_Voltages_B8 m5 : 50|9@1+ (0.01,0) [0|5.12] "V" Vector__XXX
 SG_ BMS_Voltages_B9 m6 : 5|9@1+ (0.01,0) [0|5.12] "V" Vector__XXX
 SG_ BMS_Voltages_B10 m6 : 14|9@1+ (0.01,0) [0|5.12] "V" Vector__XXX
 SG_ BMS_Voltages_B11 m6 : 23|9@1+ (0.01,0) [0|5.12] "V" Vector__XXX
 SG_ BMS_Voltages_B12 m6 : 32|9@1+ (0.01,0) [0|5.12] "V" Vector__XXX
 SG_ BMS_Voltages_B13 m6 : 41|9@1+ (0.01,0) [0|5.12] "V" Vector__XXX
 SG_ BMS_Voltages_B14 m6 : 50|9@1+ (0.01,0) [0|5.12] "V" Vector__XXX
 SG_ BMS_Voltages_B15 m7 : 5|9@1+ (0.01,0) [0|5.12] "V" Vector__XXX
 SG_ BMS_Voltages_B16 m7 : 14|9@1+ (0.01,0) [0|5.12] "V" Vector__XXX
 SG_ BMS_Voltages_B17 m7 : 23|9@1+ (0.01,0) [0|5.12] "V" Vector__XXX
 SG_ BMS_Voltages_B18 m7 : 32|9@1+ (0.01,0) [0|5.12] "V" Vector__XXX
 SG_ BMS_Voltages_B19 m7 : 41|9@1+ (0.01,0) [0|5.12] "V" Vector__XXX
 SG_ BMS_Voltages_B20 m7 : 50|9@1+ (0.01,0) [0|5.12] "V" Vector__XXX
 SG_ BMS_Voltages_B21 m8 : 5|9@1+ (0.01,0) [0|5.12] "V" Vector__XXX
 SG_ BMS_Voltages_B22 m8 : 14|9@1+ (0.01,0) [0|5.12] "V" Vector__XXX
 SG_ BMS_Voltages_B23 m8 : 23|9@1+ (0.01,0) [0|5.12] "V" Vector__XXX
 SG_ BMS_Voltages_B24 m8 : 32|9@1+ (0.01,0) [0|5.12] "V" Vector__XXX
 SG_ BMS_Voltages_B25 m8 : 41|9@1+ (0.01,0) [0|5.12] "V" Vector__XXX
 SG_ BMS_Voltages_B26 m8 : 50|9@1+ (0.01,0) [0|5.12] "V" Vector__XXX
 SG_ BMS_Voltages_C0 m9 : 5|9@1+ (0.01,0) [0|5.12] "V" Vector__XXX
 SG_ BMS_Voltages_C1 m9 : 14|9@1+ (0.01,0) [0|5.12] "V" Vector__XXX
 SG_ BMS_Voltages_C2 m9 : 23|9@1+ (0.01,0) [0|5.12] "V" Vector__XXX
 SG_ BMS_Voltages_C3 m9 : 32|9@1+ (0.01,0) [0|5.12] "V" Vector__XXX
 SG_ BMS_Voltages_C4 m9 : 41|9@1+ (0.01,0) [0|5.12] "V" Vector__XXX
 SG_ BMS_Voltages_C5 m9 : 50|9@1+ (0.01,0) [0|5.12] "V" Vector__XXX
 SG_ BMS_Voltages_C6 m10 : 5|9@1+ (0.01,0) [0|5.12] "V" Vector__XXX
 SG_ BMS_Voltages_C7 m10 : 14|9@1+ (0.01,0) [0|5.12] "V" Vector__XXX
 SG_ BMS_Voltages_C8 m10 : 23|9@1+ (0.01,0) [0|5.12] "V" Vector__XXX
 SG_ BMS_Voltages_C9 m10 : 32|9@1+ (0.01,0) [0|5.12] "V" Vector__XXX
 SG_ BMS_Voltages_C10 m10 : 41|9@1+ (0.01,0) [0|5.12] "V" Vector__XXX
 SG_ BMS_Voltages_C11 m10 : 50|9@1+ (0.01,0) [0|5.12] "V" Vector__XXX
 SG_ BMS_Voltages_C12 m11 : 5|9@1+ (0.01,0) [0|5.12] "V" Vector__XXX
 SG_ BMS_Voltages_C13 m11 : 14|9@1+ (0.01,0) [0|5.12] "V" Vector__XXX
 SG_ BMS_Voltages_C14 m11 : 23|9@1+ (0.01,0) [0|5.12] "V" Vector__XXX
 SG_ BMS_Voltages_C15 m11 : 32|9@1+ (0.01,0) [0|5.12] "V" Vector__XXX
 SG_ BMS_Voltages_C16 m11 : 41|9@1+ (0.01,0) [0|5.12] "V" Vector__XXX
 SG_ BMS_Voltages_C17 m11 : 50|9@1+ (0.01,0) [0|5.12] "V" Vector__XXX
 SG_ BMS_Voltages_C18 m12 : 5|9@1+ (0.01,0) [0|5.12] "V" Vector__XXX
 SG_ BMS_Voltages_C19 m12 : 14|9@1+ (0.01,0) [0|5.12] "V" Vector__XXX
 SG_ BMS_Voltages_C20 m12 : 23|9@1+ (0.01,0) [0|5.12] "V" Vector__XXX
 SG_ BMS_Voltages_C21 m12 : 32|9@1+ (0.01,0) [0|5.12] "V" Vector__XXX
 SG_ BMS_Voltages_C22 m12 : 41|9@1+ (0.01,0) [0|5.12] "V" Vector__XXX
 SG_ BMS_Voltages_C23 m12 : 50|9@1+ (0.01,0) [0|5.12] "V" Vector__XXX
 SG_ BMS_Voltages_C24 m13 : 5|9@1+ (0.01,0) [0|5.12] "V" Vector__XXX
 SG_ BMS_Voltages_C25 m13 : 14|9@1+ (0.01,0) [0|5.12] "V" Vector__XXX
 SG_ BMS_Voltages_C26 m13 : 23|9@1+ (0.01,0) [0|5.12] "V" Vector__XXX
 SG_ BMS_Voltages_D0 m13 : 32|9@1+ (0.01,0) [0|5.12] "V" Vector__XXX
 SG_ BMS_Voltages_D1 m13 : 41|9@1+ (0.01,0) [0|5.12] "V" Vector__XXX
 SG_ BMS_Voltages_D2 m13 : 50|9@1+ (0.01,0) [0|5.12] "V" Vector__XXX
 SG_ BMS_Voltages_D3 m14 : 5|9@1+ (0.01,0) [0|5.12] "V" Vector__XXX
 SG_ BMS_Voltages_D4 m14 : 14|9@1+ (0.01,0) [0|5.12] "V" Vector__XXX
 SG_ BMS_Voltages_D5 m14 : 23|9@1+ (0.01,0) [0|5.12] "V" Vector__XXX
 SG_ BMS_Voltages_D6 m14 : 32|9@1+ (0.01,0) [0|5.12] "V" Vector__XXX
 SG_ BMS_Voltages_D7 m14 : 41|9@1+ (0.01,0) [0|5.12] "V" Vector__XXX
 SG_ BMS_Voltages_D8 m14 : 50|9@1+ (0.01,0) [0|5.12] "V" Vector__XXX
 SG_ BMS_Voltages_D9 m15 : 5|9@1+ (0.01,0) [0|5.12] "V" Vector__XXX
 SG_ BMS_Voltages_D10 m15 : 14|9@1+ (0.01,0) [0|5.12] "V" Vector__XXX
 SG_ BMS_Voltages_D11 m15 : 23|9@1+ (0.01,0) [0|5.12] "V" Vector__XXX
 SG_ BMS_Voltages_D12 m15 : 32|9@1+ (0.01,0) [0|5.12] "V" Vector__XXX
 SG_ BMS_Voltages_D13 m15 : 41|9@1+ (0.01,0) [0|5.12] "V" Vector__XXX
 SG_ BMS_Voltages_D14 m15 : 50|9@1+ (0.01,0) [0|5.12] "V" Vector__XXX
 SG_ BMS_Voltages_D15 m16 : 5|9@1+ (0.01,0) [0|5.12] "V" Vector__XXX
 SG_ BMS_Voltages_D16 m16 : 14|9@1+ (0.01,0) [0|5.12] "V" Vector__XXX
 SG_ BMS_Voltages_D17 m16 : 23|9@1+ (0.01,0) [0|5.12] "V" Vector__XXX
 SG_ BMS_Voltages_D18 m16 : 32|9@1+ (0.01,0) [0|5.12] "V" Vector__XXX
 SG_ BMS_Voltages_D19 m16 : 41|9@1+ (0.01,0) [0|5.12] "V" Vector__XXX
 SG_ BMS_Voltages_D20 m16 : 50|9@1+ (0.01,0) [0|5.12] "V" Vector__XXX
 SG_ BMS_Voltages_D21 m17 : 5|9@1+ (0.01,0) [0|5.12] "V" Vector__XXX
 SG_ BMS_Voltages_D22 m17 : 14|9@1+ (0.01,0) [0|5.12] "V" Vector__XXX
 SG_ BMS_Voltages_D23 m17 : 23|9@1+ (0.01,0) [0|5.12] "V" Vector__XXX
 SG_ BMS_Voltages_D24 m17 : 32|9@1+ (0.01,0) [0|5.12] "V" Vector__XXX
 SG_ BMS_Voltages_D25 m17 : 41|9@1+ (0.01,0) [0|5.12] "V" Vector__XXX
 SG_ BMS_Voltages_D26 m17 : 50|9@1+ (0.01,0) [0|5.12] "V" Vector__XXX
 SG_ BMS_Voltages_E0 m18 : 5|9@1+ (0.01,0) [0|5.12] "V" Vector__XXX
 SG_ BMS_Voltages_E1 m18 : 14|9@1+ (0.01,0) [0|5.12] "V" Vector__XXX
 SG_ BMS_Voltages_E2 m18 : 23|9@1+ (0.01,0) [0|5.12] "V" Vector__XXX
 SG_ BMS_Voltages_E3 m18 : 32|9@1+ (0.01,0) [0|5.12] "V" Vector__XXX
 SG_ BMS_Voltages_E4 m18 : 41|9@1+ (0.01,0) [0|5.12] "V" Vector__XXX
 SG_ BMS_Voltages_E5 m18 : 50|9@1+ (0.01,0) [0|5.12] "V" Vector__XXX
 SG_ BMS_Voltages_E6 m19 : 5|9@1+ (0.01,0) [0|5.12] "V" Vector__XXX
 SG_ BMS_Voltages_E7 m19 : 14|9@1+ (0.01,0) [0|5.12] "V" Vector__XXX
 SG_ BMS_Voltages_E8 m19 : 23|9@1+ (0.01,0) [0|5.12] "V" Vector__XXX
 SG_ BMS_Voltages_E9 m19 : 32|9@1+ (0.01,0) [0|5.12] "V" Vector__XXX
 SG_ BMS_Voltages_E10 m19 : 41|9@1+ (0.01,0) [0|5.12] "V" Vector__XXX
 SG_ BMS_Voltages_E11 m19 : 50|9@1+ (0.01,0) [0|5.12] "V" Vector__XXX
 SG_ BMS_Voltages_E12 m20 : 5|9@1+ (0.01,0) [0|5.12] "V" Vector__XXX
 SG_ BMS_Voltages_E13 m20 : 14|9@1+ (0.01,0) [0|5.12] "V" Vector__XXX
 SG_ BMS_Voltages_E14 m20 : 23|9@1+ (0.01,0) [0|5.12] "V" Vector__XXX
 SG_ BMS_Voltages_E15 m20 : 32|9@1+ (0.01,0) [0|5.12] "V" Vector__XXX
 SG_ BMS_Voltages_E16 m20 : 41|9@1+ (0.01,0) [0|5.12] "V" Vector__XXX
 SG_ BMS_Voltages_E17 m20 : 50|9@1+ (0.01,0) [0|5.12] "V" Vector__XXX
 SG_ BMS_Voltages_E18 m21 : 5|9@1+ (0.01,0) [0|5.12] "V" Vector__XXX
 SG_ BMS_Voltages_E19 m21 : 14|9@1+ (0.01,0) [0|5.12] "V" Vector__XXX
 SG_ BMS_Voltages_E20 m21 : 23|9@1+ (0.01,0) [0|5.12] "V" Vector__XXX
 SG_ BMS_Voltages_E21 m21 : 32|9@1+ (0.01,0) [0|5.12] "V" Vector__XXX
 SG_ BMS_Voltages_E22 m21 : 41|9@1+ (0.01,0) [0|5.12] "V" Vector__XXX
 SG_ BMS_Voltages_E23 m21 : 50|9@1+ (0.01,0) [0|5.12] "V" Vector__XXX
 SG_ BMS_Voltages_E24 m22 : 5|9@1+ (0.01,0) [0|5.12] "V" Vector__XXX
 SG_ BMS_Voltages_E25 m22 : 14|9@1+ (0.01,0) [0|5.12] "V" Vector__XXX
 SG_ BMS_Voltages_E26 m22 : 23|9@1+ (0.01,0) [0|5.12] "V" Vector__XXX

BO_ 621 BMS_ChipVoltages: 8 BMS
 SG_ BMS_Chip_Voltages_mux M : 0|2@1+ (1,0) [0|2] "V" Vector__XXX
 SG_ BMS_Chip_Voltages_A0 m0 : 2|13@1+ (0.01,0) [0|81.92] "V" Vector__XXX
 SG_ BMS_Chip_Voltages_A1 m0 : 15|13@1+ (0.01,0) [0|81.92] "V" Vector__XXX
 SG_ BMS_Chip_Voltages_B0 m0 : 28|13@1+ (0.01,0) [0|81.92] "V" Vector__XXX
 SG_ BMS_Chip_Voltages_B1 m0 : 41|13@1+ (0.01,0) [0|81.92] "V" Vector__XXX
 SG_ BMS_Chip_Voltages_C0 m1 : 2|13@1+ (0.01,0) [0|81.92] "V" Vector__XXX
 SG_ BMS_Chip_Voltages_C1 m1 : 15|13@1+ (0.01,0) [0|81.92] "V" Vector__XXX
 SG_ BMS_Chip_Voltages_D0 m1 : 28|13@1+ (0.01,0) [0|81.92] "V" Vector__XXX
 SG_ BMS_Chip_Voltages_D1 m1 : 41|13@1+ (0.01,0) [0|81.92] "V" Vector__XXX
 SG_ BMS_Chip_Voltages_E0 m2 : 2|13@1+ (0.01,0) [0|81.92] "V" Vector__XXX
 SG_ BMS_Chip_Voltages_E1 m2 : 15|13@1+ (0.01,0) [0|81.92] "V" Vector__XXX

BO_ 622 BMS_Temperatures: 8 BMS
 SG_ BMS_Temperatures_mux M : 0|3@1+ (1,0) [0|7] "" Vector__XXX
 SG_ BMS_Temperatures_A0 m0 : 3|10@1+ (0.1,0) [0|102.3] "C" Vector__XXX
 SG_ BMS_Temperatures_A1 m0 : 13|10@1+ (0.1,0) [0|102.3] "C" Vector__XXX
 SG_ BMS_Temperatures_A2 m0 : 23|10@1+ (0.1,0) [0|102.3] "C" Vector__XXX
 SG_ BMS_Temperatures_A3 m0 : 33|10@1+ (0.1,0) [0|102.3] "C" Vector__XXX
 SG_ BMS_Temperatures_A4 m0 : 43|10@1+ (0.1,0) [0|102.3] "C" Vector__XXX
 SG_ BMS_Temperatures_A5 m0 : 53|10@1+ (0.1,0) [0|102.3] "C" Vector__XXX
 SG_ BMS_Temperatures_B0 m1 : 3|10@1+ (0.1,0) [0|102.3] "C" Vector__XXX
 SG_ BMS_Temperatures_B1 m1 : 13|10@1+ (0.1,0) [0|102.3] "C" Vector__XXX
 SG_ BMS_Temperatures_B2 m1 : 23|10@1+ (0.1,0) [0|102.3] "C" Vector__XXX
 SG_ BMS_Temperatures_B3 m1 : 33|10@1+ (0.1,0) [0|102.3] "C" Vector__XXX
 SG_ BMS_Temperatures_B4 m1 : 43|10@1+ (0.1,0) [0|102.3] "C" Vector__XXX
 SG_ BMS_Temperatures_B5 m1 : 53|10@1+ (0.1,0) [0|102.3] "C" Vector__XXX
 SG_ BMS_Temperatures_C0 m2 : 3|10@1+ (0.1,0) [0|102.3] "C" Vector__XXX
 SG_ BMS_Temperatures_C1 m2 : 13|10@1+ (0.1,0) [0|102.3] "C" Vector__XXX
 SG_ BMS_Temperatures_C2 m2 : 23|10@1+ (0.1,0) [0|102.3] "C" Vector__XXX
 SG_ BMS_Temperatures_C3 m2 : 33|10@1+ (0.1,0) [0|102.3] "C" Vector__XXX
 SG_ BMS_Temperatures_C4 m2 : 43|10@1+ (0.1,0) [0|102.3] "C" Vector__XXX
 SG_ BMS_Temperatures_C5 m2 : 53|10@1+ (0.1,0) [0|102.3] "C" Vector__XXX
 SG_ BMS_Temperatures_D0 m3 : 3|10@1+ (0.1,0) [0|102.3] "C" Vector__XXX
 SG_ BMS_Temperatures_D1 m3 : 13|10@1+ (0.1,0) [0|102.3] "C" Vector__XXX
 SG_ BMS_Temperatures_D2 m3 : 23|10@1+ (0.1,0) [0|102.3] "C" Vector__XXX
 SG_ BMS_Temperatures_D3 m3 : 33|10@1+ (0.1,0) [0|102.3] "C" Vector__XXX
 SG_ BMS_Temperatures_D4 m3 : 43|10@1+ (0.1,0) [0|102.3] "C" Vector__XXX
 SG_ BMS_Temperatures_D5 m3 : 53|10@1+ (0.1,0) [0|102.3] "C" Vector__XXX
 SG_ BMS_Temperatures_E0 m4 : 3|10@1+ (0.1,0) [0|102.3] "C" Vector__XXX
 SG_ BMS_Temperatures_E1 m4 : 13|10@1+ (0.1,0) [0|102.3] "C" Vector__XXX
 SG_ BMS_Temperatures_E2 m4 : 23|10@1+ (0.1,0) [0|102.3] "C" Vector__XXX
 SG_ BMS_Temperatures_E3 m4 : 33|10@1+ (0.1,0) [0|102.3] "C" Vector__XXX
 SG_ BMS_Temperatures_E4 m4 : 43|10@1+ (0.1,0) [0|102.3] "C" Vector__XXX
 SG_ BMS_Temperatures_E5 m4 : 53|10@1+ (0.1,0) [0|102.3] "C" Vector__XXX

BO_ 623 BMS_ThermistorVoltages: 8 BMS
 SG_ BMS_ThermistorVoltages_mux M : 0|3@1+ (1,0) [0|5] "" Vector__XXX
 SG_ BMS_ThermistorVoltages_A0 m0 : 3|9@1+ (0.01,0) [0|5.12] "V" Vector__XXX
 SG_ BMS_ThermistorVoltages_A1 m0 : 12|9@1+ (0.01,0) [0|5.12] "V" Vector__XXX
 SG_ BMS_ThermistorVoltages_A2 m0 : 21|9@1+ (0.01,0) [0|5.12] "V" Vector__XXX
 SG_ BMS_ThermistorVoltages_A3 m0 : 30|9@1+ (0.01,0) [0|5.12] "V" Vector__XXX
 SG_ BMS_ThermistorVoltages_A4 m0 : 39|9@1+ (0.01,0) [0|5.12] "V" Vector__XXX
 SG_ BMS_ThermistorVoltages_A5 m0 : 48|9@1+ (0.01,0) [0|5.12] "V" Vector__XXX
 SG_ BMS_ThermistorVoltages_B0 m1 : 3|9@1+ (0.01,0) [0|5.12] "V" Vector__XXX
 SG_ BMS_ThermistorVoltages_B1 m1 : 12|9@1+ (0.01,0) [0|5.12] "V" Vector__XXX
 SG_ BMS_ThermistorVoltages_B2 m1 : 21|9@1+ (0.01,0) [0|5.12] "V" Vector__XXX
 SG_ BMS_ThermistorVoltages_B3 m1 : 30|9@1+ (0.01,0) [0|5.12] "V" Vector__XXX
 SG_ BMS_ThermistorVoltages_B4 m1 : 39|9@1+ (0.01,0) [0|5.12] "V" Vector__XXX
 SG_ BMS_ThermistorVoltages_B5 m1 : 48|9@1+ (0.01,0) [0|5.12] "V" Vector__XXX
 SG_ BMS_ThermistorVoltages_C0 m2 : 3|9@1+ (0.01,0) [0|5.12] "V" Vector__XXX
 SG_ BMS_ThermistorVoltages_C1 m2 : 12|9@1+ (0.01,0) [0|5.12] "V" Vector__XXX
 SG_ BMS_ThermistorVoltages_C2 m2 : 21|9@1+ (0.01,0) [0|5.12] "V" Vector__XXX
 SG_ BMS_ThermistorVoltages_C3 m2 : 30|9@1+ (0.01,0) [0|5.12] "V" Vector__XXX
 SG_ BMS_ThermistorVoltages_C4 m2 : 39|9@1+ (0.01,0) [0|5.12] "V" Vector__XXX
 SG_ BMS_ThermistorVoltages_C5 m2 : 48|9@1+ (0.01,0) [0|5.12] "V" Vector__XXX
 SG_ BMS_ThermistorVoltages_D0 m3 : 3|9@1+ (0.01,0) [0|5.12] "V" Vector__XXX
 SG_ BMS_ThermistorVoltages_D1 m3 : 12|9@1+ (0.01,0) [0|5.12] "V" Vector__XXX
 SG_ BMS_ThermistorVoltages_D2 m3 : 21|9@1+ (0.01,0) [0|5.12] "V" Vector__XXX
 SG_ BMS_ThermistorVoltages_D3 m3 : 30|9@1+ (0.01,0) [0|5.12] "V" Vector__XXX
 SG_ BMS_ThermistorVoltages_D4 m3 : 39|9@1+ (0.01,0) [0|5.12] "V" Vector__XXX
 SG_ BMS_ThermistorVoltages_D5 m3 : 48|9@1+ (0.01,0) [0|5.12] "V" Vector__XXX
 SG_ BMS_ThermistorVoltages_E0 m4 : 3|9@1+ (0.01,0) [0|5.12] "V" Vector__XXX
 SG_ BMS_ThermistorVoltages_E1 m4 : 12|9@1+ (0.01,0) [0|5.12] "V" Vector__XXX
 SG_ BMS_ThermistorVoltages_E2 m4 : 21|9@1+ (0.01,0) [0|5.12] "V" Vector__XXX
 SG_ BMS_ThermistorVoltages_E3 m4 : 30|9@1+ (0.01,0) [0|5.12] "V" Vector__XXX
 SG_ BMS_ThermistorVoltages_E4 m4 : 39|9@1+ (0.01,0) [0|5.12] "V" Vector__XXX
 SG_ BMS_ThermistorVoltages_E5 m4 : 48|9@1+ (0.01,0) [0|5.12] "V" Vector__XXX

BO_ 624 BMS_DrainStatus: 8 BMS
 SG_ BMS_DrainStatus M : 0|2@1+ (1,0) [0|3] "" Vector__XXX
 SG_ BMS_DrainStatus_A1 m0 : 3|1@1+ (1,0) [0|1] "" Vector__XXX
 SG_ BMS_DrainStatus_A2 m0 : 4|1@1+ (1,0) [0|1] "" Vector__XXX
 SG_ BMS_DrainStatus_A3 m0 : 5|1@1+ (1,0) [0|1] "" Vector__XXX
 SG_ BMS_DrainStatus_A4 m0 : 6|1@1+ (1,0) [0|1] "" Vector__XXX
 SG_ BMS_DrainStatus_A5 m0 : 7|1@1+ (1,0) [0|1] "" Vector__XXX
 SG_ BMS_DrainStatus_A6 m0 : 8|1@1+ (1,0) [0|1] "" Vector__XXX
 SG_ BMS_DrainStatus_A7 m0 : 9|1@1+ (1,0) [0|1] "" Vector__XXX
 SG_ BMS_DrainStatus_A8 m0 : 10|1@1+ (1,0) [0|1] "" Vector__XXX
 SG_ BMS_DrainStatus_A9 m0 : 11|1@1+ (1,0) [0|1] "" Vector__XXX
 SG_ BMS_DrainStatus_A10 m0 : 12|1@1+ (1,0) [0|1] "" Vector__XXX
 SG_ BMS_DrainStatus_A11 m0 : 13|1@1+ (1,0) [0|1] "" Vector__XXX
 SG_ BMS_DrainStatus_A12 m0 : 14|1@1+ (1,0) [0|1] "" Vector__XXX
 SG_ BMS_DrainStatus_A13 m0 : 15|1@1+ (1,0) [0|1] "" Vector__XXX
 SG_ BMS_DrainStatus_A14 m0 : 16|1@1+ (1,0) [0|1] "" Vector__XXX
 SG_ BMS_DrainStatus_A15 m0 : 17|1@1+ (1,0) [0|1] "" Vector__XXX
 SG_ BMS_DrainStatus_A16 m0 : 18|1@1+ (1,0) [0|1] "" Vector__XXX
 SG_ BMS_DrainStatus_A17 m0 : 19|1@1+ (1,0) [0|1] "" Vector__XXX
 SG_ BMS_DrainStatus_B1 m0 : 20|1@1+ (1,0) [0|1] "" Vector__XXX
 SG_ BMS_DrainStatus_B2 m0 : 21|1@1+ (1,0) [0|1] "" Vector__XXX
 SG_ BMS_DrainStatus_B3 m0 : 22|1@1+ (1,0) [0|1] "" Vector__XXX
 SG_ BMS_DrainStatus_B4 m0 : 23|1@1+ (1,0) [0|1] "" Vector__XXX
 SG_ BMS_DrainStatus_B5 m0 : 24|1@1+ (1,0) [0|1] "" Vector__XXX
 SG_ BMS_DrainStatus_B6 m0 : 25|1@1+ (1,0) [0|1] "" Vector__XXX
 SG_ BMS_DrainStatus_B7 m0 : 26|1@1+ (1,0) [0|1] "" Vector__XXX
 SG_ BMS_DrainStatus_B8 m0 : 27|1@1+ (1,0) [0|1] "" Vector__XXX
 SG_ BMS_DrainStatus_B9 m0 : 28|1@1+ (1,0) [0|1] "" Vector__XXX
 SG_ BMS_DrainStatus_B10 m0 : 29|1@1+ (1,0) [0|1] "" Vector__XXX
 SG_ BMS_DrainStatus_B11 m0 : 30|1@1+ (1,0) [0|1] "" Vector__XXX
 SG_ BMS_DrainStatus_B12 m0 : 31|1@1+ (1,0) [0|1] "" Vector__XXX
 SG_ BMS_DrainStatus_B13 m0 : 32|1@1+ (1,0) [0|1] "" Vector__XXX
 SG_ BMS_DrainStatus_B14 m0 : 33|1@1+ (1,0) [0|1] "" Vector__XXX
 SG_ BMS_DrainStatus_B15 m0 : 34|1@1+ (1,0) [0|1] "" Vector__XXX
 SG_ BMS_DrainStatus_B16 m0 : 35|1@1+ (1,0) [0|1] "" Vector__XXX
 SG_ BMS_DrainStatus_B17 m0 : 36|1@1+ (1,0) [0|1] "" Vector__XXX
 SG_ BMS_DrainStatus_C1 m0 : 37|1@1+ (1,0) [0|1] "" Vector__XXX
 SG_ BMS_DrainStatus_C2 m0 : 38|1@1+ (1,0) [0|1] "" Vector__XXX
 SG_ BMS_DrainStatus_C3 m0 : 39|1@1+ (1,0) [0|1] "" Vector__XXX
 SG_ BMS_DrainStatus_C4 m0 : 40|1@1+ (1,0) [0|1] "" Vector__XXX
 SG_ BMS_DrainStatus_C5 m0 : 41|1@1+ (1,0) [0|1] "" Vector__XXX
 SG_ BMS_DrainStatus_C6 m0 : 42|1@1+ (1,0) [0|1] "" Vector__XXX
 SG_ BMS_DrainStatus_C7 m0 : 43|1@1+ (1,0) [0|1] "" Vector__XXX
 SG_ BMS_DrainStatus_C8 m0 : 44|1@1+ (1,0) [0|1] "" Vector__XXX
 SG_ BMS_DrainStatus_C9 m0 : 45|1@1+ (1,0) [0|1] "" Vector__XXX
 SG_ BMS_DrainStatus_C10 m0 : 46|1@1+ (1,0) [0|1] "" Vector__XXX
 SG_ BMS_DrainStatus_C11 m0 : 47|1@1+ (1,0) [0|1] "" Vector__XXX
 SG_ BMS_DrainStatus_C12 m0 : 48|1@1+ (1,0) [0|1] "" Vector__XXX
 SG_ BMS_DrainStatus_C13 m0 : 49|1@1+ (1,0) [0|1] "" Vector__XXX
 SG_ BMS_DrainStatus_C14 m0 : 50|1@1+ (1,0) [0|1] "" Vector__XXX
 SG_ BMS_DrainStatus_C15 m0 : 51|1@1+ (1,0) [0|1] "" Vector__XXX
 SG_ BMS_DrainStatus_C16 m0 : 52|1@1+ (1,0) [0|1] "" Vector__XXX
 SG_ BMS_DrainStatus_C17 m0 : 53|1@1+ (1,0) [0|1] "" Vector__XXX
 SG_ BMS_DrainStatus_D1 m0 : 54|1@1+ (1,0) [0|1] "" Vector__XXX
 SG_ BMS_DrainStatus_D2 m0 : 55|1@1+ (1,0) [0|1] "" Vector__XXX
 SG_ BMS_DrainStatus_D3 m0 : 56|1@1+ (1,0) [0|1] "" Vector__XXX
 SG_ BMS_DrainStatus_D4 m0 : 57|1@1+ (1,0) [0|1] "" Vector__XXX
 SG_ BMS_DrainStatus_D5 m0 : 58|1@1+ (1,0) [0|1] "" Vector__XXX
 SG_ BMS_DrainStatus_D6 m0 : 59|1@1+ (1,0) [0|1] "" Vector__XXX
 SG_ BMS_DrainStatus_D7 m0 : 60|1@1+ (1,0) [0|1] "" Vector__XXX
 SG_ BMS_DrainStatus_D8 m0 : 61|1@1+ (1,0) [0|1] "" Vector__XXX
 SG_ BMS_DrainStatus_D9 m0 : 62|1@1+ (1,0) [0|1] "" Vector__XXX
 SG_ BMS_DrainStatus_D10 m0 : 63|1@1+ (1,0) [0|1] "" Vector__XXX
 SG_ BMS_DrainStatus_D11 m1 : 3|1@1+ (1,0) [0|1] "" Vector__XXX
 SG_ BMS_DrainStatus_D12 m1 : 4|1@1+ (1,0) [0|1] "" Vector__XXX
 SG_ BMS_DrainStatus_D13 m1 : 5|1@1+ (1,0) [0|1] "" Vector__XXX
 SG_ BMS_DrainStatus_D14 m1 : 6|1@1+ (1,0) [0|1] "" Vector__XXX
 SG_ BMS_DrainStatus_D15 m1 : 7|1@1+ (1,0) [0|1] "" Vector__XXX
 SG_ BMS_DrainStatus_D16 m1 : 8|1@1+ (1,0) [0|1] "" Vector__XXX
 SG_ BMS_DrainStatus_D17 m1 : 9|1@1+ (1,0) [0|1] "" Vector__XXX
 SG_ BMS_DrainStatus_E1 m1 : 10|1@1+ (1,0) [0|1] "" Vector__XXX
 SG_ BMS_DrainStatus_E2 m1 : 11|1@1+ (1,0) [0|1] "" Vector__XXX
 SG_ BMS_DrainStatus_E3 m1 : 12|1@1+ (1,0) [0|1] "" Vector__XXX
 SG_ BMS_DrainStatus_E4 m1 : 13|1@1+ (1,0) [0|1] "" Vector__XXX
 SG_ BMS_DrainStatus_E5 m1 : 14|1@1+ (1,0) [0|1] "" Vector__XXX
 SG_ BMS_DrainStatus_E6 m1 : 15|1@1+ (1,0) [0|1] "" Vector__XXX
 SG_ BMS_DrainStatus_E7 m1 : 16|1@1+ (1,0) [0|1] "" Vector__XXX
 SG_ BMS_DrainStatus_E8 m1 : 17|1@1+ (1,0) [0|1] "" Vector__XXX
 SG_ BMS_DrainStatus_E9 m1 : 18|1@1+ (1,0) [0|1] "" Vector__XXX
 SG_ BMS_DrainStatus_E10 m1 : 19|1@1+ (1,0) [0|1] "" Vector__XXX
 SG_ BMS_DrainStatus_E11 m1 : 20|1@1+ (1,0) [0|1] "" Vector__XXX
 SG_ BMS_DrainStatus_E12 m1 : 21|1@1+ (1,0) [0|1] "" Vector__XXX
 SG_ BMS_DrainStatus_E13 m1 : 22|1@1+ (1,0) [0|1] "" Vector__XXX
 SG_ BMS_DrainStatus_E14 m1 : 23|1@1+ (1,0) [0|1] "" Vector__XXX
 SG_ BMS_DrainStatus_E15 m1 : 24|1@1+ (1,0) [0|1] "" Vector__XXX
 SG_ BMS_DrainStatus_E16 m1 : 25|1@1+ (1,0) [0|1] "" Vector__XXX
 SG_ BMS_DrainStatus_E17 m1 : 26|1@1+ (1,0) [0|1] "" Vector__XXX
 SG_ BMS_DrainStatus_F1 m1 : 27|1@1+ (1,0) [0|1] "" Vector__XXX
 SG_ BMS_DrainStatus_F2 m1 : 28|1@1+ (1,0) [0|1] "" Vector__XXX
 SG_ BMS_DrainStatus_F3 m1 : 29|1@1+ (1,0) [0|1] "" Vector__XXX
 SG_ BMS_DrainStatus_F4 m1 : 30|1@1+ (1,0) [0|1] "" Vector__XXX
 SG_ BMS_DrainStatus_F5 m1 : 31|1@1+ (1,0) [0|1] "" Vector__XXX
 SG_ BMS_DrainStatus_F6 m1 : 32|1@1+ (1,0) [0|1] "" Vector__XXX
 SG_ BMS_DrainStatus_F7 m1 : 33|1@1+ (1,0) [0|1] "" Vector__XXX
 SG_ BMS_DrainStatus_F8 m1 : 34|1@1+ (1,0) [0|1] "" Vector__XXX
 SG_ BMS_DrainStatus_F9 m1 : 35|1@1+ (1,0) [0|1] "" Vector__XXX
 SG_ BMS_DrainStatus_F10 m1 : 36|1@1+ (1,0) [0|1] "" Vector__XXX
 SG_ BMS_DrainStatus_F11 m1 : 37|1@1+ (1,0) [0|1] "" Vector__XXX
 SG_ BMS_DrainStatus_F12 m1 : 38|1@1+ (1,0) [0|1] "" Vector__XXX
 SG_ BMS_DrainStatus_F13 m1 : 39|1@1+ (1,0) [0|1] "" Vector__XXX
 SG_ BMS_DrainStatus_F14 m1 : 40|1@1+ (1,0) [0|1] "" Vector__XXX
 SG_ BMS_DrainStatus_F15 m1 : 41|1@1+ (1,0) [0|1] "" Vector__XXX
 SG_ BMS_DrainStatus_F16 m1 : 42|1@1+ (1,0) [0|1] "" Vector__XXX
 SG_ BMS_DrainStatus_F17 m1 : 43|1@1+ (1,0) [0|1] "" Vector__XXX
 SG_ BMS_DrainStatus_G1 m1 : 44|1@1+ (1,0) [0|1] "" Vector__XXX
 SG_ BMS_DrainStatus_G2 m1 : 45|1@1+ (1,0) [0|1] "" Vector__XXX
 SG_ BMS_DrainStatus_G3 m1 : 46|1@1+ (1,0) [0|1] "" Vector__XXX
 SG_ BMS_DrainStatus_G4 m1 : 47|1@1+ (1,0) [0|1] "" Vector__XXX
 SG_ BMS_DrainStatus_G5 m1 : 48|1@1+ (1,0) [0|1] "" Vector__XXX
 SG_ BMS_DrainStatus_G6 m1 : 49|1@1+ (1,0) [0|1] "" Vector__XXX
 SG_ BMS_DrainStatus_G7 m1 : 50|1@1+ (1,0) [0|1] "" Vector__XXX
 SG_ BMS_DrainStatus_G8 m1 : 51|1@1+ (1,0) [0|1] "" Vector__XXX
 SG_ BMS_DrainStatus_G9 m1 : 52|1@1+ (1,0) [0|1] "" Vector__XXX
 SG_ BMS_DrainStatus_G10 m1 : 53|1@1+ (1,0) [0|1] "" Vector__XXX
 SG_ BMS_DrainStatus_G11 m1 : 54|1@1+ (1,0) [0|1] "" Vector__XXX
 SG_ BMS_DrainStatus_G12 m1 : 55|1@1+ (1,0) [0|1] "" Vector__XXX
 SG_ BMS_DrainStatus_G13 m1 : 56|1@1+ (1,0) [0|1] "" Vector__XXX
 SG_ BMS_DrainStatus_G14 m1 : 57|1@1+ (1,0) [0|1] "" Vector__XXX
 SG_ BMS_DrainStatus_G15 m1 : 58|1@1+ (1,0) [0|1] "" Vector__XXX
 SG_ BMS_DrainStatus_G16 m1 : 59|1@1+ (1,0) [0|1] "" Vector__XXX
 SG_ BMS_DrainStatus_G17 m1 : 60|1@1+ (1,0) [0|1] "" Vector__XXX
 SG_ BMS_DrainStatus_H1 m1 : 61|1@1+ (1,0) [0|1] "" Vector__XXX
 SG_ BMS_DrainStatus_H2 m1 : 62|1@1+ (1,0) [0|1] "" Vector__XXX
 SG_ BMS_DrainStatus_H3 m1 : 63|1@1+ (1,0) [0|1] "" Vector__XXX
 SG_ BMS_DrainStatus_H4 m2 : 3|1@1+ (1,0) [0|1] "" Vector__XXX
 SG_ BMS_DrainStatus_H5 m2 : 4|1@1+ (1,0) [0|1] "" Vector__XXX
 SG_ BMS_DrainStatus_H6 m2 : 5|1@1+ (1,0) [0|1] "" Vector__XXX
 SG_ BMS_DrainStatus_H7 m2 : 6|1@1+ (1,0) [0|1] "" Vector__XXX
 SG_ BMS_DrainStatus_H8 m2 : 7|1@1+ (1,0) [0|1] "" Vector__XXX
 SG_ BMS_DrainStatus_H9 m2 : 8|1@1+ (1,0) [0|1] "" Vector__XXX
 SG_ BMS_DrainStatus_H10 m2 : 9|1@1+ (1,0) [0|1] "" Vector__XXX
 SG_ BMS_DrainStatus_H11 m2 : 10|1@1+ (1,0) [0|1] "" Vector__XXX
 SG_ BMS_DrainStatus_H12 m2 : 11|1@1+ (1,0) [0|1] "" Vector__XXX
 SG_ BMS_DrainStatus_H13 m2 : 12|1@1+ (1,0) [0|1] "" Vector__XXX
 SG_ BMS_DrainStatus_H14 m2 : 13|1@1+ (1,0) [0|1] "" Vector__XXX
 SG_ BMS_DrainStatus_H15 m2 : 14|1@1+ (1,0) [0|1] "" Vector__XXX
 SG_ BMS_DrainStatus_H16 m2 : 15|1@1+ (1,0) [0|1] "" Vector__XXX
 SG_ BMS_DrainStatus_H17 m2 : 16|1@1+ (1,0) [0|1] "" Vector__XXX

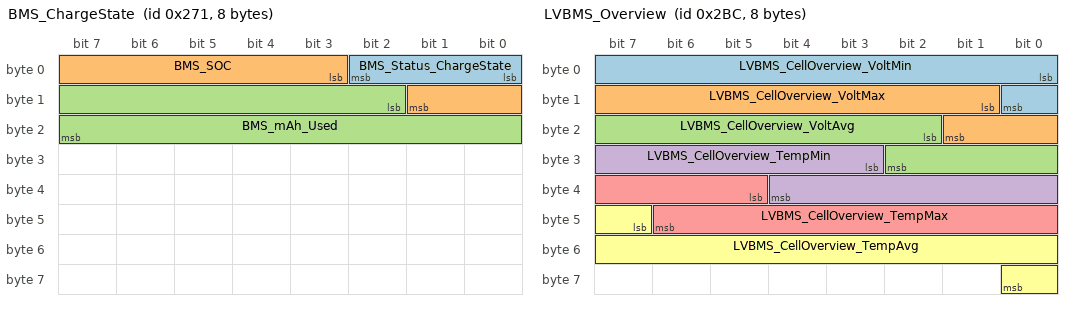
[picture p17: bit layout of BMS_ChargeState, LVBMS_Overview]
BO_ 625 BMS_ChargeState: 8 BMS
 SG_ BMS_Status_ChargeState : 0|3@1+ (1,0) [0|7] "" Vector__XXX
 SG_ BMS_SOC : 3|7@1+ (1,0) [0|100] "%" Vector__XXX
 SG_ BMS_mAh_Used : 10|14@1+ (1,0) [0|11800] "mAh" Vector__XXX

BO_ 700 LVBMS_Overview: 8 LVBMS
 SG_ LVBMS_CellOverview_VoltMin : 0|9@1+ (0.01,0) [0|5.12] "V" Vector__XXX
 SG_ LVBMS_CellOverview_VoltMax : 9|9@1+ (0.01,0) [0|5.12] "V" Vector__XXX
 SG_ LVBMS_CellOverview_VoltAvg : 18|9@1+ (0.01,0) [0|5.12] "V" Vector__XXX
 SG_ LVBMS_CellOverview_TempMin : 27|10@1+ (0.1,0) [0|102.3] "C" Vector__XXX
 SG_ LVBMS_CellOverview_TempMax : 37|10@1+ (0.1,0) [0|102.3] "C" Vector__XXX
 SG_ LVBMS_CellOverview_TempAvg : 47|10@1+ (0.1,0) [0|102.3] "C" Vector__XXX

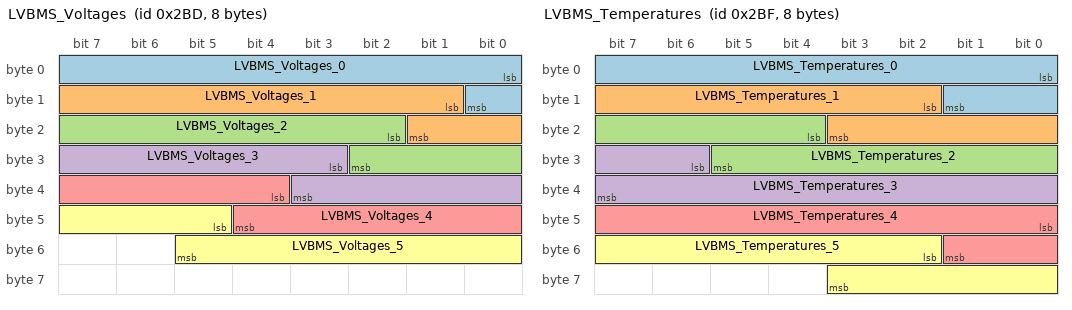
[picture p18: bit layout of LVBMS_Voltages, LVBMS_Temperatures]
BO_ 701 LVBMS_Voltages: 8 LVBMS
 SG_ LVBMS_Voltages_0 : 0|9@1+ (0.01,0) [0|5.12] "V" Vector__XXX
 SG_ LVBMS_Voltages_1 : 9|9@1+ (0.01,0) [0|5.12] "V" Vector__XXX
 SG_ LVBMS_Voltages_2 : 18|9@1+ (0.01,0) [0|5.12] "V" Vector__XXX
 SG_ LVBMS_Voltages_3 : 27|9@1+ (0.01,0) [0|5.12] "V" Vector__XXX
 SG_ LVBMS_Voltages_4 : 36|9@1+ (0.01,0) [0|5.12] "V" Vector__XXX
 SG_ LVBMS_Voltages_5 : 45|9@1+ (0.01,0) [0|5.12] "V" Vector__XXX

BO_ 702 LVBMS_PackData: 8 LVBMS
 SG_ LVBMS_Chip_Voltage : 0|13@1+ (0.01,0) [0|81.91] "V" Vector__XXX
 SG_ LVBMS_ChargeState : 13|4@1+ (1,0) [0|0] "" Vector__XXX

BO_ 703 LVBMS_Temperatures: 8 LVBMS
 SG_ LVBMS_Temperatures_0 : 0|10@1+ (0.1,0) [0|102.3] "C" Vector__XXX
 SG_ LVBMS_Temperatures_1 : 10|10@1+ (0.1,0) [0|102.3] "C" Vector__XXX
 SG_ LVBMS_Temperatures_2 : 20|10@1+ (0.1,0) [0|102.3] "C" Vector__XXX
 SG_ LVBMS_Temperatures_3 : 30|10@1+ (0.1,0) [0|102.3] "C" Vector__XXX
 SG_ LVBMS_Temperatures_4 : 40|10@1+ (0.1,0) [0|102.3] "C" Vector__XXX
 SG_ LVBMS_Temperatures_5 : 50|10@1+ (0.1,0) [0|102.3] "C" Vector__XXX

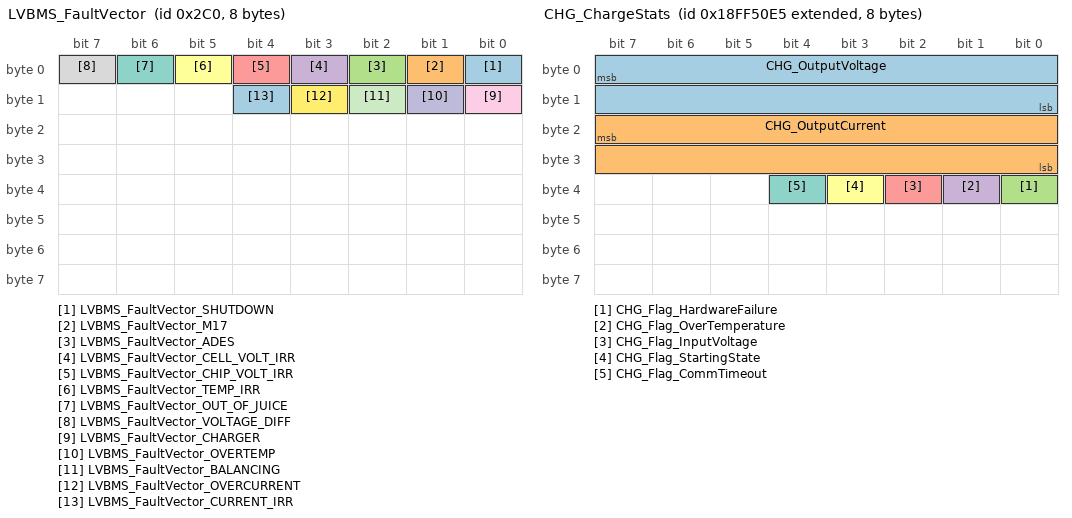
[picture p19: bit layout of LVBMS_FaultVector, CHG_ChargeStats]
BO_ 704 LVBMS_FaultVector: 8 LVBMS
 SG_ LVBMS_FaultVector_SHUTDOWN : 0|1@1+ (1,0) [0|1] ""  Vector__XXX
 SG_ LVBMS_FaultVector_M17 : 1|1@1+ (1,0) [0|1] ""  Vector__XXX
 SG_ LVBMS_FaultVector_ADES : 2|1@1+ (1,0) [0|1] ""  Vector__XXX
 SG_ LVBMS_FaultVector_CELL_VOLT_IRR : 3|1@1+ (1,0) [0|1] ""  Vector__XXX
 SG_ LVBMS_FaultVector_CHIP_VOLT_IRR : 4|1@1+ (1,0) [0|1] ""  Vector__XXX
 SG_ LVBMS_FaultVector_TEMP_IRR : 5|1@1+ (1,0) [0|1] ""  Vector__XXX
 SG_ LVBMS_FaultVector_OUT_OF_JUICE : 6|1@1+ (1,0) [0|1] ""  Vector__XXX
 SG_ LVBMS_FaultVector_VOLTAGE_DIFF : 7|1@1+ (1,0) [0|1] ""  Vector__XXX
 SG_ LVBMS_FaultVector_CHARGER : 8|1@1+ (1,0) [0|1] ""  Vector__XXX
 SG_ LVBMS_FaultVector_OVERTEMP : 9|1@1+ (1,0) [0|1] ""  Vector__XXX
 SG_ LVBMS_FaultVector_BALANCING : 10|1@1+ (1,0) [0|1] ""  Vector__XXX
 SG_ LVBMS_FaultVector_OVERCURRENT : 11|1@1+ (1,0) [0|1] ""  Vector__XXX
 SG_ LVBMS_FaultVector_CURRENT_IRR : 12|1@1+ (1,0) [0|1] ""  Vector__XXX

BO_ 705 LVBMS_ErrorCodes: 8 LVBMS
 SG_ LVBMS_ErrorCodes_TX_NOT_RECIEVED : 0|1@1+ (1,0) [0|1] ""  Vector__XXX
 SG_ LVBMS_ErrorCodes_TX_LOOPBACK_MISMATCH : 1|1@1+ (1,0) [0|1] ""  Vector__XXX
 SG_ LVBMS_ErrorCodes_NUM_CHIPS_MISMATCH : 2|1@1+ (1,0) [0|1] ""  Vector__XXX
 SG_ LVBMS_ErrorCodes_LSSM_BYTE : 3|1@1+ (1,0) [0|1] ""  Vector__XXX
 SG_ LVBMS_ErrorCodes_LSSM_COMM_ERR : 4|1@1+ (1,0) [0|1] ""  Vector__XXX
 SG_ LVBMS_ErrorCodes_ALERT_RX : 5|1@1+ (1,0) [0|1] ""  Vector__XXX
 SG_ LVBMS_ErrorCodes_ALERT_RX_OVERFLOW : 6|1@1+ (1,0) [0|1] ""  Vector__XXX
 SG_ LVBMS_ErrorCodes_LDQ_READ : 7|1@1+ (1,0) [0|1] ""  Vector__XXX
 SG_ LVBMS_ErrorCodes_LDQ_FULL : 8|1@1+ (1,0) [0|1] ""  Vector__XXX
 SG_ LVBMS_ErrorCodes_RX_TIMEOUT : 9|1@1+ (1,0) [0|1] ""  Vector__XXX
 SG_ LVBMS_ErrorCodes_NO_RX : 10|1@1+ (1,0) [0|1] ""  Vector__XXX
 SG_ LVBMS_ErrorCodes_ADES_SCAN_TIMEOUT : 11|1@1+ (1,0) [0|1] ""  Vector__XXX
 SG_ LVBMS_ErrorCodes_RX_STATUS : 12|1@1+ (1,0) [0|1] ""  Vector__XXX
 SG_ LVBMS_ErrorCodes_TX_NOT_WRITTEN : 13|1@1+ (1,0) [0|1] ""  Vector__XXX
 SG_ LVBMS_ErrorCodes_NO_WAKE : 14|1@1+ (1,0) [0|1] ""  Vector__XXX
 SG_ LVBMS_ErrorCodes_BALANCING_NO_INIT : 15|1@1+ (1,0) [0|1] ""  Vector__XXX
 SG_ LVBMS_ErrorCodes_BALANCING_FAULT : 16|1@1+ (1,0) [0|1] ""  Vector__XXX
 SG_ LVBMS_ErrorCodes_CHARGING_DISCONNECTED : 17|1@1+ (1,0) [0|1] ""  Vector__XXX

BO_ 706 LVBMS_Current: 8 BMS
 SG_ LVBMS_InstCurrentFilt : 0|32@1- (0.001,0) [-100|250] "A"  Vector__XXX

BO_ 2550588916 CHG_ChargeRequest: 8 BMS
 SG_ CHG_ChargeRequest_MaxVoltage : 7|16@0+ (0.1,0) [0|6553.5] "V"  CHG
 SG_ CHG_ChargeRequest_MaxCurrent : 23|16@0+ (0.1,0) [0|6553.5] "A"  CHG
 SG_ CHG_ChargeRequest_Control : 32|1@0+ (1,0) [0|1] ""  CHG

BO_ 2566869221 CHG_ChargeStats: 8 CHG
 SG_ CHG_OutputVoltage : 7|16@0+ (0.1,0) [0|6553.5] "V" Vector__XXX
 SG_ CHG_OutputCurrent : 23|16@0+ (0.1,0) [0|6553.5] "A" Vector__XXX
 SG_ CHG_Flag_HardwareFailure : 32|1@1+ (1,0) [0|1] "" Vector__XXX
 SG_ CHG_Flag_OverTemperature : 33|1@1+ (1,0) [0|1] "" Vector__XXX
 SG_ CHG_Flag_InputVoltage : 34|1@1+ (1,0) [0|1] "" Vector__XXX
 SG_ CHG_Flag_StartingState : 35|1@1+ (1,0) [0|1] "" Vector__XXX
 SG_ CHG_Flag_CommTimeout : 36|1@1+ (1,0) [0|1] "" Vector__XXX

BO_ 2566845491 TPMS_TirePressure: 8 TPMS
 SG_ TPMS_TireNum M : 7|8@0+ (1,0) [1|4] "" Vector__XXX
 SG_ TPMS_T1_TirePressure m1 : 15|16@0+ (1,0) [0|0] "kPa" Vector__XXX
 SG_ TPMS_T1_TireTemp m1 : 31|8@0+ (1,0) [0|0] "degC" Vector__XXX
 SG_ TPMS_T1_Voltage m1 : 39|8@0+ (0.1,0) [0|0] "V" Vector__XXX
 SG_ TPMS_T1_Leak m1 : 40|1@0+ (1,0) [0|0] "" Vector__XXX
 SG_ TPMS_T1_MinusTemp m1 : 44|1@0+ (1,0) [0|0] "" Vector__XXX
 SG_ TPMS_T1_Error m1 : 45|1@0+ (1,0) [0|0] "" Vector__XXX
 SG_ TPMS_T2_TirePressure m2 : 15|16@0+ (1,0) [0|0] "kPa" Vector__XXX
 SG_ TPMS_T2_TireTemp m2 : 31|8@0+ (1,0) [0|0] "degC" Vector__XXX
 SG_ TPMS_T2_Voltage m2 : 39|8@0+ (0.1,0) [0|0] "V" Vector__XXX
 SG_ TPMS_T2_Leak m2 : 40|1@0+ (1,0) [0|0] "" Vector__XXX
 SG_ TPMS_T2_MinusTemp m2 : 44|1@0+ (1,0) [0|0] "" Vector__XXX
 SG_ TPMS_T2_Error m2 : 45|1@0+ (1,0) [0|0] "" Vector__XXX
 SG_ TPMS_T3_TirePressure m3 : 15|16@0+ (1,0) [0|0] "kPa" Vector__XXX
 SG_ TPMS_T3_TireTemp m3 : 31|8@0+ (1,0) [0|0] "degC" Vector__XXX
 SG_ TPMS_T3_Voltage m3 : 39|8@0+ (0.1,0) [0|0] "V" Vector__XXX
 SG_ TPMS_T3_Leak m3 : 40|1@0+ (1,0) [0|0] "" Vector__XXX
 SG_ TPMS_T3_MinusTemp m3 : 44|1@0+ (1,0) [0|0] "" Vector__XXX
 SG_ TPMS_T3_Error m3 : 45|1@0+ (1,0) [0|0] "" Vector__XXX
 SG_ TPMS_T4_TirePressure m4 : 15|16@0+ (1,0) [0|0] "kPa" Vector__XXX
 SG_ TPMS_T4_TireTemp m4 : 31|8@0+ (1,0) [0|0] "degC" Vector__XXX
 SG_ TPMS_T4_Voltage m4 : 39|8@0+ (0.1,0) [0|0] "V" Vector__XXX
 SG_ TPMS_T4_Leak m4 : 40|1@0+ (1,0) [0|0] "" Vector__XXX
 SG_ TPMS_T4_MinusTemp m4 : 44|1@0+ (1,0) [0|0] "" Vector__XXX
 SG_ TPMS_T4_Error m4 : 45|1@0+ (1,0) [0|0] "" Vector__XXX

VAL_ 625 BMS_Status_ChargeState 0 "DISCONNECTED" 1 "CONNECTED" 2 "CONNECTED_CHARGING" 3 "CONNECTED_SETTLING" 4 "CONNECTED_BALANCING" 5 "CONNECTED_COMPLETE" 6 "CONNECTED_FAULTED";

CM_ BU_ FDL "Front driverless actuation";
CM_ BU_ C70 "Bosch C70 Data Logger";
CM_ BU_ PIT "EvoScann P8-A Pressure Sensor";
CM_ BU_ IRTEMP "Izze IRTS-60 v2 IR Temperature Sensors";
CM_ BU_ VectorNav "VectorNav IMU";
CM_ BU_ DS "Driverless system";
CM_ BU_ SSDB "SSDB";

SIG_VALTYPE_ 400 VectorNav_AccelX : 1;
SIG_VALTYPE_ 400 VectorNav_AccelY : 1;
SIG_VALTYPE_ 401 VectorNav_AccelZ : 1;
SIG_VALTYPE_ 401 VectorNav_AngularRateX : 1;
SIG_VALTYPE_ 402 VectorNav_AngularRateY : 1;
SIG_VALTYPE_ 402 VectorNav_AngularRateZ : 1;
SIG_VALTYPE_ 403 VectorNav_PosLlaL : 2;
SIG_VALTYPE_ 404 VectorNav_PosLlaO : 2;
SIG_VALTYPE_ 405 VectorNav_PosLlaA : 2;
SIG_VALTYPE_ 406 VectorNav_VelBodyX : 1;
SIG_VALTYPE_ 406 VectorNav_VelBodyY : 1;
SIG_VALTYPE_ 407 VectorNav_VelBodyZ : 1;
SIG_VALTYPE_ 407 VectorNav_YprY : 1;
SIG_VALTYPE_ 408 VectorNav_YprP : 1;
SIG_VALTYPE_ 408 VectorNav_YprR : 1;
SIG_VALTYPE_ 410 VectorNav_BodySlip : 1;
